VERSION "volvo_v40_2017_ptradar"

NS_ :

BS_:

BU_: XXX BCM CEM CVM DIM ECM FSM PSCM SAS SRS TCM Gateway ESR

BO_ 8 SAS0: 8 SAS
 SG_ SteeringDirection : 42|1@0+ (1,0) [0|1] "" XXX
 SG_ RelativeTurnDirection : 43|1@0+ (1,0) [0|1] "" XXX
 SG_ SteeringAngle : 53|14@0+ (0.04395,0) [0|65535] "degrees" XXX
 SG_ NEW_SIGNAL_1 : 47|4@0+ (1,0) [0|15] "" XXX
 SG_ NEW_SIGNAL_2 : 39|4@0+ (1,0) [0|15] "" XXX
 SG_ AngleRate : 21|14@0+ (0.075,0) [0|1500] "deg/S" XXX

BO_ 16 CCButtons: 8 CEM
 SG_ byte0 : 7|8@0+ (1,0) [0|255] "" XXX
 SG_ byte1 : 15|8@0+ (1,0) [0|255] "" XXX
 SG_ byte2 : 23|8@0+ (1,0) [0|255] "" XXX
 SG_ byte3 : 31|8@0+ (1,0) [0|255] "" XXX
 SG_ byte4 : 39|8@0+ (1,0) [0|255] "" XXX
 SG_ byte6 : 55|5@0+ (1,0) [0|31] "" XXX
 SG_ B7b0 : 56|1@0+ (1,0) [0|1] "" XXX
 SG_ B7b1 : 57|1@0+ (1,0) [0|1] "" XXX
 SG_ B7b6 : 62|1@0+ (1,0) [0|1] "" XXX
 SG_ ACCOnOffBtn : 58|1@0+ (1,0) [0|1] "" XXX
 SG_ ACCSetBtn : 63|1@0+ (1,0) [0|1] "" XXX
 SG_ ACCStopBtn : 60|1@0+ (1,0) [0|1] "" XXX
 SG_ ACCResumeBtn : 61|1@0+ (1,0) [0|1] "" XXX
 SG_ ACCMinusBtn : 48|1@0+ (1,0) [0|1] "" XXX
 SG_ TimeGapIncreaseBtn : 49|1@0+ (1,0) [0|1] "" XXX
 SG_ TimeGapDecreaseBtn : 50|1@0+ (1,0) [0|1] "" XXX
 SG_ byte5 : 47|8@0+ (1,0) [0|255] "" XXX
 SG_ B7b3 : 59|1@0+ (1,0) [0|1] "" XXX

BO_ 48 FSM0: 8 FSM
 SG_ ACCStatusTracking : 56|1@0+ (1,0) [0|1] "" XXX
 SG_ ACCStatusOnOff : 57|1@0+ (1,0) [0|1] "" XXX
 SG_ ACCStatusActive : 58|1@0+ (1,0) [0|1] "" XXX
 SG_ FCWSomething : 25|3@0+ (1,0) [0|3] "" XXX
 SG_ StatusSomething : 55|8@0+ (1,0) [0|255] "" XXX

BO_ 64 TCM0: 8 TCM
 SG_ RPMSomething : 42|11@0+ (1,0) [0|2047] "" XXX
 SG_ GearShifter : 46|2@0+ (1,0) [0|3] "" XXX

BO_ 85 PedalandBrake: 8 ECM
 SG_ AccPedal : 9|10@0+ (0.1,0) [0|1023] "%" XXX
 SG_ BrakePedalActive2 : 24|1@0+ (1,0) [0|1] "" XXX
 SG_ NEW_SIGNAL_1 : 35|12@0+ (1,0) [0|4095] "" XXX
 SG_ BrakePedalActive : 38|1@0+ (1,0) [0|1] "" XXX
 SG_ NEW_SIGNAL_3 : 55|8@0+ (1,0) [0|255] "" XXX
 SG_ NEW_SIGNAL_2 : 63|8@0+ (1,0) [0|255] "" XXX

BO_ 101 EngineInfo: 8 XXX
 SG_ NEW_SIGNAL_1 : 17|10@0+ (1,-512) [0|1023] "" XXX
 SG_ EngineSpeed : 52|13@0+ (1,0) [0|1023] "" XXX

BO_ 112 NEW_MSG_4: 8 XXX
 SG_ NEW_SIGNAL_1 : 39|8@0+ (1,0) [0|255] "" XXX

BO_ 114 ECM1: 8 ECM
 SG_ NEW_SIGNAL_1 : 23|8@0+ (1,0) [0|255] "" XXX
 SG_ ECM_ACC_ONOFF_INV : 43|1@0+ (1,0) [0|1] "" XXX
 SG_ ECM_ACC_RESUME_INV : 45|1@0+ (1,0) [0|1] "" XXX
 SG_ ECM_ACC_SET_INV : 47|1@0+ (1,0) [0|1] "" XXX
 SG_ ECM_ACC_TIMEGAP_INC_INV : 33|1@0+ (1,0) [0|1] "" XXX
 SG_ ECM_ACC_DEC_INV : 32|1@0+ (1,0) [0|1] "" XXX
 SG_ ECM_ACC_TIMEGAP_DEC_INV : 34|1@0+ (1,0) [0|1] "" XXX

BO_ 117 ECM1_2: 8 ECM

BO_ 128 NEW_MSG_5: 8 XXX
 SG_ NEW_SIGNAL_2 : 26|11@0+ (1,0) [0|2047] "" XXX
 SG_ NEW_SIGNAL_1 : 52|13@0+ (1,0) [0|8191] "" XXX

BO_ 176 ECM2: 8 ECM
 SG_ NEW_SIGNAL_1 : 50|11@0+ (1,0) [0|2047] "" XXX
 SG_ NEW_SIGNAL_2 : 47|8@0+ (1,0) [0|63] "" XXX

BO_ 192 Gear: 8 XXX
 SG_ TransmissionGear : 36|3@0+ (1,1) [0|7] "" XXX

BO_ 208 FSM1: 8 FSM
 SG_ SET_X_E3 : 7|8@0+ (1,0) [0|255] "" XXX
 SG_ SET_X_B4 : 15|8@0+ (1,0) [0|255] "" XXX
 SG_ SET_X_08 : 23|8@0+ (1,0) [0|255] "" XXX
 SG_ TrqLim : 31|8@0+ (1,-128) [0|255] "" XXX
 SG_ Checksum : 55|8@0+ (1,0) [0|255] "" XXX
 SG_ LKASteerDirection : 57|2@0+ (1,0) [0|2] "" XXX
 SG_ SET_X_25 : 63|6@0+ (1,0) [0|63] "" XXX
 SG_ LKAAngleReq : 37|14@0+ (0.04395,-360.0384) [-360.0384|359.99445] "degrees" XXX
 SG_ SET_X_02 : 39|2@0+ (1,0) [0|3] "" XXX

BO_ 224 PSCM0: 8 PSCM
 SG_ NEW_SIGNAL_2 : 12|5@0+ (1,0) [0|31] "" XXX
 SG_ counter_07 : 15|3@0+ (1,0) [0|7] "" XXX
 SG_ counter2_07 : 37|3@0+ (1,0) [0|16383] "" XXX
 SG_ rate_of_something : 46|7@0+ (1,0) [0|62] "" XXX
 SG_ OneDuringDriving : 49|1@0+ (1,0) [0|1] "" XXX
 SG_ NEW_SIGNAL_1 : 63|1@0+ (1,0) [0|1] "" XXX

BO_ 245 wheelspeed0: 8 BCM
 SG_ counter1 : 21|6@0+ (1,0) [0|65535] "" XXX
 SG_ counter0 : 7|16@0+ (1,0) [0|65535] "" XXX
 SG_ WhlSpdLF : 39|16@0+ (1,0) [0|65535] "" XXX
 SG_ WhlSpdRF : 55|16@0+ (1,0) [0|65535] "" XXX

BO_ 272 SpeedSignal0: 8 XXX
 SG_ VehicleSpeedSignal : 55|16@0+ (0.01,0) [0|65535] "" XXX

BO_ 288 wheel_speed1: 8 BCM
 SG_ WhlSpdLR : 39|16@0+ (1,0) [0|65535] "" XXX
 SG_ WhlSpdRR : 55|16@0+ (1,0) [0|65535] "" XXX

BO_ 293 PSCM1: 8 PSCM
 SG_ byte0 : 7|8@0+ (1,0) [0|255] "" XXX
 SG_ byte3 : 31|8@0+ (1,0) [0|255] "" XXX
 SG_ byte4 : 39|8@0+ (1,0) [0|255] "" XXX
 SG_ byte7 : 63|8@0+ (1,0) [0|255] "" XXX
 SG_ LKATorque : 11|12@0+ (1,-2000) [0|4095] "" XXX
 SG_ SteeringAngleServo : 47|16@0+ (0.04395,-1440.1536) [0|65535] "deg" XXX
 SG_ LKAActive : 15|4@0+ (1,0) [0|15] "" XXX

BO_ 304 VehicleSpeed0: 8 BCM
 SG_ NEW_SIGNAL_2 : 15|16@0+ (1,0) [0|65535] "" XXX
 SG_ VehicleSpeed : 31|16@0+ (0.01,0) [0|65535] "km/h" XXX
 SG_ NEW_SIGNAL_1 : 55|16@0+ (1,0) [0|65535] "" XXX

VAL_TABLE_ ForwardReverse 1 "Reverse" 0 "Forward" ;
VAL_TABLE_ LeftRight 1 "Right Clockwise" 0 "Left CounterClockwise" ;
VAL_TABLE_ ValidInvalid 1 "Valid" 0 "Invalid" ;
VAL_TABLE_ TrueFalse 1 "True" 0 "False" ;

BO_ 325 ECM3: 8 ECM

BO_ 336 VehicleSpeed1: 8 BCM
 SG_ NEW_SIGNAL_2 : 31|16@0+ (1,0) [0|65535] "" XXX
 SG_ NEW_SIGNAL_1 : 15|16@0+ (1,0) [0|65535] "" XXX
 SG_ VehicleSpeed : 55|16@0+ (0.01,0) [0|65535] "" XXX

BO_ 352 FSM2: 8 FSM
 SG_ LkaDimLine : 51|2@1+ (1,0) [0|127] "" XXX
 SG_ ACC_AccelRequest : 63|8@0+ (0.066,-12.672) [-12.672|4.158] "m/s^2" XXX
 SG_ NEW_SIGNAL_1 : 55|1@0+ (1,0) [0|1] "" XXX
 SG_ Byte_0 : 7|8@0+ (1,0) [0|255] "" XXX
 SG_ Byte_1 : 15|8@0+ (1,0) [0|255] "" XXX
 SG_ Byte_2_b7_6 : 23|2@0+ (1,0) [0|3] "" XXX
 SG_ ACC_BrakeRequest : 21|1@0+ (1,0) [0|1] "" XXX
 SG_ Byte_2_b4_0 : 20|5@0+ (1,0) [0|31] "" XXX
 SG_ Byte_3 : 31|8@0+ (1,0) [0|255] "" XXX
 SG_ Byte_4 : 39|8@0+ (1,0) [0|255] "" XXX
 SG_ Byte_5_b7_6 : 47|2@0+ (1,0) [0|3] "" XXX
 SG_ ACC_BrakeRequest_B : 45|1@0+ (1,0) [0|1] "" XXX
 SG_ Byte_5_b4_0 : 44|5@0+ (1,0) [0|31] "" XXX

BO_ 432 BrakeMessages: 8 BCM
 SG_ BrakePress0 : 1|10@0+ (1,0) [0|1023] "" XXX
 SG_ BrakePress1 : 33|10@0+ (1,0) [0|1023] "" XXX
 SG_ BrakeStatus : 18|3@0+ (1,0) [0|7] "" XXX
 SG_ BrakeHold : 22|1@0+ (1,0) [0|1] "" XXX

BO_ 437 BrakeInfo: 8 XXX
 SG_ Byte_0 : 7|8@0+ (1,0) [0|255] "" XXX
 SG_ Byte_1 : 15|8@0+ (1,0) [0|255] "" XXX
 SG_ Byte_2 : 23|8@0+ (1,0) [0|255] "" XXX
 SG_ Byte_3 : 31|8@0+ (1,0) [0|255] "" XXX
 SG_ Byte_4 : 39|8@0+ (1,0) [0|255] "" XXX
 SG_ Byte_5 : 47|8@0+ (1,0) [0|255] "" XXX
 SG_ Byte_6 : 55|8@0+ (1,0) [0|255] "" XXX
 SG_ Byte_7 : 63|8@0+ (1,0) [0|255] "" XXX

BO_ 464 DIM0: 8 DIM

BO_ 480 BCM0: 8 BCM

BO_ 528 CEM0: 8 CEM
 SG_ LKA_State : 2|1@0+ (1,0) [0|1] "" XXX

BO_ 608 CVM0: 8 CVM
 SG_ NEW_SIGNAL_1 : 7|8@0+ (1,0) [0|255] "" XXX
 SG_ NEW_SIGNAL_2 : 15|5@0+ (1,0) [0|32] "" XXX
 SG_ Distance : 10|11@0+ (1,0) [0|2048] "" XXX

BO_ 624 FSM3: 8 FSM
 SG_ Byte_0 : 7|8@0+ (1,0) [0|255] "" XXX
 SG_ Byte_1 : 15|8@0+ (1,0) [0|255] "" XXX
 SG_ ACC_LeadDecelRaw : 23|16@0- (1,0) [-32768|32767] "" XXX
 SG_ Byte_4 : 39|8@0+ (1,0) [0|255] "" XXX
 SG_ Byte_5 : 47|8@0+ (1,0) [0|255] "" XXX
 SG_ Byte_6 : 55|8@0+ (1,0) [0|255] "" XXX
 SG_ Byte_7 : 63|8@0+ (1,0) [0|255] "" XXX

BO_ 640 FSM4: 8 FSM
 SG_ Byte_0 : 7|8@0+ (1,0) [0|255] "" XXX
 SG_ Byte_1 : 15|8@0+ (1,0) [0|255] "" XXX
 SG_ Byte_2 : 23|8@0+ (1,0) [0|255] "" XXX
 SG_ Byte_3 : 31|8@0+ (1,0) [0|255] "" XXX
 SG_ Byte_4 : 39|8@0+ (1,0) [0|255] "" XXX
 SG_ SpeedTarget : 47|8@0+ (1,0) [0|255] "" XXX
 SG_ Byte_6_b7_6 : 55|2@0+ (1,0) [0|3] "" XXX
 SG_ Byte_6_b5_3 : 53|3@0+ (1,0) [0|7] "" XXX
 SG_ Byte_6_b2 : 50|1@0+ (1,0) [0|1] "" XXX
 SG_ ACC_TractionRequest : 49|10@0+ (1,0) [0|1023] "" XXX

BO_ 648 SRS0: 8 SRS

BO_ 652 ECM4: 8 ECM

BO_ 656 ECM5: 8 ECM

BO_ 657 ECM6: 8 ECM

BO_ 681 MiscCarInfo: 8 CEM
 SG_ TurnSignal : 1|2@0+ (1,0) [0|3] "" XXX
 SG_ HighBeamOn : 52|1@0+ (1,0) [0|1] "" XXX

BO_ 693 ECM7: 8 ECM

BO_ 709 ACC: 8 ECM
 SG_ SpeedTargetACC : 0|9@0+ (0.5,0) [0|511] "" XXX
 SG_ ACC_PropulsionFeedback : 63|8@0+ (1,0) [0|255] "" XXX

BO_ 853 FSM5: 8 FSM
 SG_ TargetSpeedOdo : 23|8@0+ (1,0) [0|63] "kph" XXX
 SG_ SpeedSign : 36|5@0+ (5,0) [0|32] "" XXX
 SG_ TextUnderSign : 37|1@0+ (1,0) [0|1] "" XXX
 SG_ NEW_SIGNAL_6 : 39|3@0+ (1,0) [0|3] "" XXX
 SG_ NEW_SIGNAL_5 : 47|8@0+ (1,0) [0|255] "" XXX
 SG_ NEW_SIGNAL_3 : 31|8@0+ (1,0) [0|255] "" XXX
 SG_ LaneMarkingsOdo : 15|4@0+ (1,0) [0|7] "" XXX
 SG_ NEW_SIGNAL_2 : 11|4@0+ (1,0) [0|15] "" XXX
 SG_ NEW_SIGNAL_1 : 7|8@0+ (1,0) [0|255] "" XXX
 SG_ NEW_SIGNAL_4 : 55|16@0+ (1,0) [0|65535] "" XXX

BO_ 864 CEM1: 8 CEM
 SG_ ACC_DemandChangeFlag : 39|8@0+ (1,0) [0|255] "" XXX

BO_ 912 DIM1: 8 DIM

BO_ 968 SRS1: 8 SRS
 SG_ PassengerSeatBelt : 22|1@0+ (1,0) [0|1] "" XXX
 SG_ DriverSeatBelt : 19|1@0+ (1,0) [0|1] "" XXX

BO_ 1029 CEMBCM0: 8 CEM

BO_ 1830 diagCEMReq: 8 XXX
 SG_ byte0 : 7|8@0+ (1,0) [0|255] "" XXX
 SG_ byte1 : 15|8@0+ (1,0) [0|255] "" XXX
 SG_ byte2 : 23|8@0+ (1,0) [0|255] "" XXX
 SG_ byte3 : 31|8@0+ (1,0) [0|255] "" XXX
 SG_ byte4 : 39|8@0+ (1,0) [0|255] "" XXX
 SG_ byte5 : 47|8@0+ (1,0) [0|255] "" XXX
 SG_ byte6 : 55|8@0+ (1,0) [0|255] "" XXX
 SG_ byte7 : 63|8@0+ (1,0) [0|255] "" XXX

BO_ 1838 diagCEMResp: 8 XXX
 SG_ byte03 : 7|32@0+ (1,0) [0|4294967295] "" XXX
 SG_ byte47 : 39|32@0+ (1,0) [0|4294967295] "" XXX

BO_ 1840 diagPSCMReq: 8 XXX
 SG_ byte0 : 7|8@0+ (1,0) [0|255] "" XXX
 SG_ byte1 : 15|8@0+ (1,0) [0|255] "" XXX
 SG_ byte2 : 23|8@0+ (1,0) [0|255] "" XXX
 SG_ byte3 : 31|8@0+ (1,0) [0|255] "" XXX
 SG_ byte4 : 39|8@0+ (1,0) [0|255] "" XXX
 SG_ byte5 : 47|8@0+ (1,0) [0|255] "" XXX
 SG_ byte6 : 55|8@0+ (1,0) [0|255] "" XXX
 SG_ byte7 : 63|8@0+ (1,0) [0|255] "" XXX

BO_ 1848 diagPSCMResp: 8 XXX
 SG_ byte03 : 7|32@0+ (1,0) [0|4294967295] "" XXX
 SG_ byte47 : 39|32@0+ (1,0) [0|4294967295] "" XXX

BO_ 1892 diagFSMReq: 8 XXX
 SG_ byte0 : 7|8@0+ (1,0) [0|255] "" XXX
 SG_ byte1 : 15|8@0+ (1,0) [0|255] "" XXX
 SG_ byte2 : 23|8@0+ (1,0) [0|255] "" XXX
 SG_ byte3 : 31|8@0+ (1,0) [0|255] "" XXX
 SG_ byte4 : 39|8@0+ (1,0) [0|255] "" XXX
 SG_ byte5 : 47|8@0+ (1,0) [0|255] "" XXX
 SG_ byte6 : 55|8@0+ (1,0) [0|255] "" XXX
 SG_ byte7 : 63|8@0+ (1,0) [0|255] "" XXX

BO_ 1900 diagFSMResp: 8 XXX
 SG_ byte03 : 7|32@0+ (1,0) [0|4294967295] "" XXX
 SG_ byte47 : 39|32@0+ (1,0) [0|4294967295] "" XXX

BO_ 1939 diagCVMReq: 8 XXX
 SG_ byte0 : 7|8@0+ (1,0) [0|255] "" XXX
 SG_ byte1 : 15|8@0+ (1,0) [0|255] "" XXX
 SG_ byte2 : 23|8@0+ (1,0) [0|255] "" XXX
 SG_ byte3 : 31|8@0+ (1,0) [0|255] "" XXX
 SG_ byte4 : 39|8@0+ (1,0) [0|255] "" XXX
 SG_ byte5 : 47|8@0+ (1,0) [0|255] "" XXX
 SG_ byte6 : 55|8@0+ (1,0) [0|255] "" XXX
 SG_ byte7 : 63|8@0+ (1,0) [0|255] "" XXX

BO_ 1947 diagCVMResp: 8 XXX
 SG_ byte03 : 7|32@0+ (1,0) [0|4294967295] "" XXX
 SG_ byte47 : 39|32@0+ (1,0) [0|4294967295] "" XXX

BO_ 2015 diagGlobalReq: 8 XXX
 SG_ byte0 : 7|8@0+ (1,0) [0|255] "" XXX
 SG_ byte1 : 15|8@0+ (1,0) [0|255] "" XXX
 SG_ byte2 : 23|8@0+ (1,0) [0|255] "" XXX
 SG_ byte3 : 31|8@0+ (1,0) [0|255] "" XXX
 SG_ byte4 : 39|8@0+ (1,0) [0|255] "" XXX
 SG_ byte5 : 47|8@0+ (1,0) [0|255] "" XXX
 SG_ byte6 : 55|8@0+ (1,0) [0|255] "" XXX
 SG_ byte7 : 63|8@0+ (1,0) [0|255] "" XXX

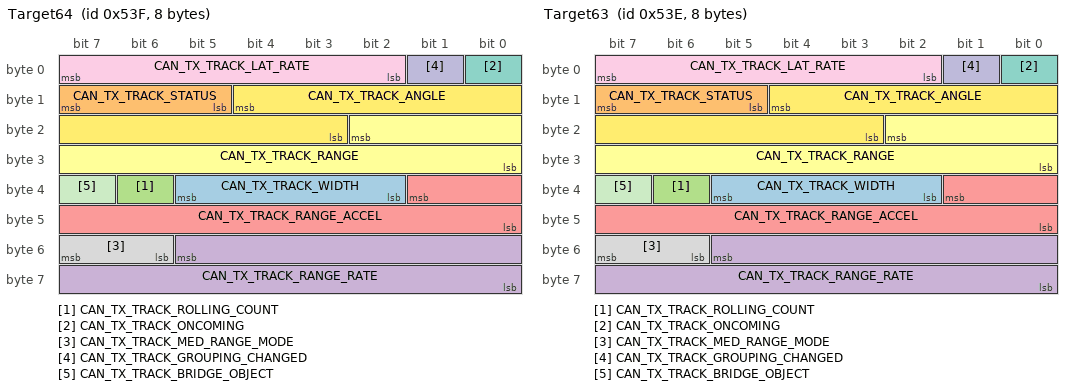
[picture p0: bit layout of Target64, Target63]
BO_ 1343 Target64: 8 Vector__XXX
 SG_ CAN_TX_TRACK_WIDTH : 37|4@0+ (0.5,0) [0|7.5] "" Vector__XXX
 SG_ CAN_TX_TRACK_STATUS : 15|3@0+ (1,0) [0|7] "" Vector__XXX
 SG_ CAN_TX_TRACK_ROLLING_COUNT : 38|1@0+ (1,0) [0|1] "" Vector__XXX
 SG_ CAN_TX_TRACK_RANGE_RATE : 53|14@0- (0.01,0) [-81.92|81.91] "m/s" Vector__XXX
 SG_ CAN_TX_TRACK_RANGE_ACCEL : 33|10@0- (0.05,0) [-25.6|25.55] "m/s^2" Vector__XXX
 SG_ CAN_TX_TRACK_RANGE : 18|11@0+ (0.1,0) [0|204.7] "m" Vector__XXX
 SG_ CAN_TX_TRACK_ONCOMING : 0|1@0+ (1,0) [0|1] "" Vector__XXX
 SG_ CAN_TX_TRACK_MED_RANGE_MODE : 55|2@0+ (1,0) [0|3] "" Vector__XXX
 SG_ CAN_TX_TRACK_LAT_RATE : 7|6@0- (0.25,0) [-8|7.75] "" Vector__XXX
 SG_ CAN_TX_TRACK_GROUPING_CHANGED : 1|1@0+ (1,0) [0|1] "" Vector__XXX
 SG_ CAN_TX_TRACK_BRIDGE_OBJECT : 39|1@0+ (1,0) [0|1] "" Vector__XXX
 SG_ CAN_TX_TRACK_ANGLE : 12|10@0- (0.1,0) [-51.2|51.1] "" Vector__XXX

BO_ 1342 Target63: 8 Vector__XXX
 SG_ CAN_TX_TRACK_WIDTH : 37|4@0+ (0.5,0) [0|7.5] "" Vector__XXX
 SG_ CAN_TX_TRACK_STATUS : 15|3@0+ (1,0) [0|7] "" Vector__XXX
 SG_ CAN_TX_TRACK_ROLLING_COUNT : 38|1@0+ (1,0) [0|1] "" Vector__XXX
 SG_ CAN_TX_TRACK_RANGE_RATE : 53|14@0- (0.01,0) [-81.92|81.91] "m/s" Vector__XXX
 SG_ CAN_TX_TRACK_RANGE_ACCEL : 33|10@0- (0.05,0) [-25.6|25.55] "m/s^2" Vector__XXX
 SG_ CAN_TX_TRACK_RANGE : 18|11@0+ (0.1,0) [0|204.7] "m" Vector__XXX
 SG_ CAN_TX_TRACK_ONCOMING : 0|1@0+ (1,0) [0|1] "" Vector__XXX
 SG_ CAN_TX_TRACK_MED_RANGE_MODE : 55|2@0+ (1,0) [0|3] "" Vector__XXX
 SG_ CAN_TX_TRACK_LAT_RATE : 7|6@0- (0.25,0) [-8|7.75] "" Vector__XXX
 SG_ CAN_TX_TRACK_GROUPING_CHANGED : 1|1@0+ (1,0) [0|1] "" Vector__XXX
 SG_ CAN_TX_TRACK_BRIDGE_OBJECT : 39|1@0+ (1,0) [0|1] "" Vector__XXX
 SG_ CAN_TX_TRACK_ANGLE : 12|10@0- (0.1,0) [-51.2|51.1] "" Vector__XXX

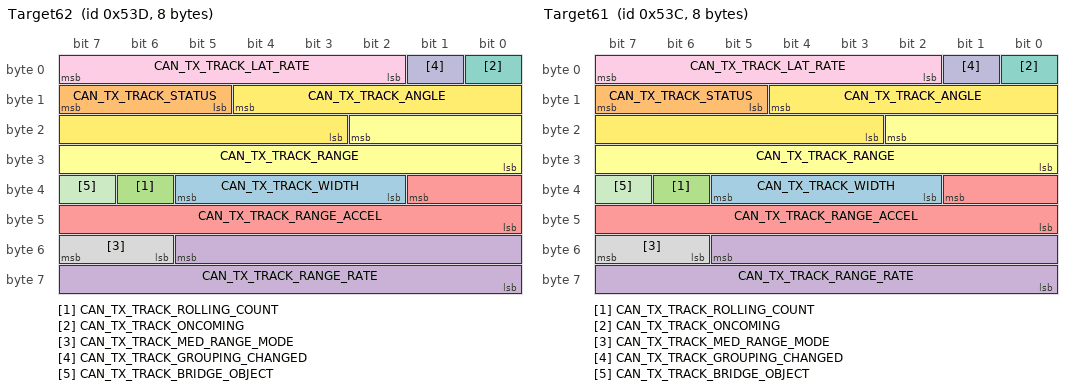
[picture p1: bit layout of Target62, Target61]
BO_ 1341 Target62: 8 Vector__XXX
 SG_ CAN_TX_TRACK_WIDTH : 37|4@0+ (0.5,0) [0|7.5] "" Vector__XXX
 SG_ CAN_TX_TRACK_STATUS : 15|3@0+ (1,0) [0|7] "" Vector__XXX
 SG_ CAN_TX_TRACK_ROLLING_COUNT : 38|1@0+ (1,0) [0|1] "" Vector__XXX
 SG_ CAN_TX_TRACK_RANGE_RATE : 53|14@0- (0.01,0) [-81.92|81.91] "m/s" Vector__XXX
 SG_ CAN_TX_TRACK_RANGE_ACCEL : 33|10@0- (0.05,0) [-25.6|25.55] "m/s^2" Vector__XXX
 SG_ CAN_TX_TRACK_RANGE : 18|11@0+ (0.1,0) [0|204.7] "m" Vector__XXX
 SG_ CAN_TX_TRACK_ONCOMING : 0|1@0+ (1,0) [0|1] "" Vector__XXX
 SG_ CAN_TX_TRACK_MED_RANGE_MODE : 55|2@0+ (1,0) [0|3] "" Vector__XXX
 SG_ CAN_TX_TRACK_LAT_RATE : 7|6@0- (0.25,0) [-8|7.75] "" Vector__XXX
 SG_ CAN_TX_TRACK_GROUPING_CHANGED : 1|1@0+ (1,0) [0|1] "" Vector__XXX
 SG_ CAN_TX_TRACK_BRIDGE_OBJECT : 39|1@0+ (1,0) [0|1] "" Vector__XXX
 SG_ CAN_TX_TRACK_ANGLE : 12|10@0- (0.1,0) [-51.2|51.1] "" Vector__XXX

BO_ 1340 Target61: 8 Vector__XXX
 SG_ CAN_TX_TRACK_WIDTH : 37|4@0+ (0.5,0) [0|7.5] "" Vector__XXX
 SG_ CAN_TX_TRACK_STATUS : 15|3@0+ (1,0) [0|7] "" Vector__XXX
 SG_ CAN_TX_TRACK_ROLLING_COUNT : 38|1@0+ (1,0) [0|1] "" Vector__XXX
 SG_ CAN_TX_TRACK_RANGE_RATE : 53|14@0- (0.01,0) [-81.92|81.91] "m/s" Vector__XXX
 SG_ CAN_TX_TRACK_RANGE_ACCEL : 33|10@0- (0.05,0) [-25.6|25.55] "m/s^2" Vector__XXX
 SG_ CAN_TX_TRACK_RANGE : 18|11@0+ (0.1,0) [0|204.7] "m" Vector__XXX
 SG_ CAN_TX_TRACK_ONCOMING : 0|1@0+ (1,0) [0|1] "" Vector__XXX
 SG_ CAN_TX_TRACK_MED_RANGE_MODE : 55|2@0+ (1,0) [0|3] "" Vector__XXX
 SG_ CAN_TX_TRACK_LAT_RATE : 7|6@0- (0.25,0) [-8|7.75] "" Vector__XXX
 SG_ CAN_TX_TRACK_GROUPING_CHANGED : 1|1@0+ (1,0) [0|1] "" Vector__XXX
 SG_ CAN_TX_TRACK_BRIDGE_OBJECT : 39|1@0+ (1,0) [0|1] "" Vector__XXX
 SG_ CAN_TX_TRACK_ANGLE : 12|10@0- (0.1,0) [-51.2|51.1] "" Vector__XXX

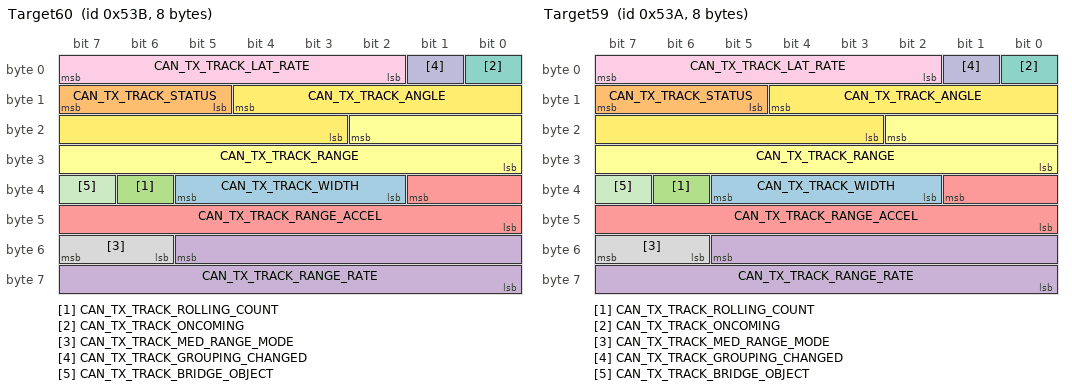
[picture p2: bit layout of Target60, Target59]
BO_ 1339 Target60: 8 Vector__XXX
 SG_ CAN_TX_TRACK_WIDTH : 37|4@0+ (0.5,0) [0|7.5] "" Vector__XXX
 SG_ CAN_TX_TRACK_STATUS : 15|3@0+ (1,0) [0|7] "" Vector__XXX
 SG_ CAN_TX_TRACK_ROLLING_COUNT : 38|1@0+ (1,0) [0|1] "" Vector__XXX
 SG_ CAN_TX_TRACK_RANGE_RATE : 53|14@0- (0.01,0) [-81.92|81.91] "m/s" Vector__XXX
 SG_ CAN_TX_TRACK_RANGE_ACCEL : 33|10@0- (0.05,0) [-25.6|25.55] "m/s^2" Vector__XXX
 SG_ CAN_TX_TRACK_RANGE : 18|11@0+ (0.1,0) [0|204.7] "m" Vector__XXX
 SG_ CAN_TX_TRACK_ONCOMING : 0|1@0+ (1,0) [0|1] "" Vector__XXX
 SG_ CAN_TX_TRACK_MED_RANGE_MODE : 55|2@0+ (1,0) [0|3] "" Vector__XXX
 SG_ CAN_TX_TRACK_LAT_RATE : 7|6@0- (0.25,0) [-8|7.75] "" Vector__XXX
 SG_ CAN_TX_TRACK_GROUPING_CHANGED : 1|1@0+ (1,0) [0|1] "" Vector__XXX
 SG_ CAN_TX_TRACK_BRIDGE_OBJECT : 39|1@0+ (1,0) [0|1] "" Vector__XXX
 SG_ CAN_TX_TRACK_ANGLE : 12|10@0- (0.1,0) [-51.2|51.1] "" Vector__XXX

BO_ 1338 Target59: 8 Vector__XXX
 SG_ CAN_TX_TRACK_WIDTH : 37|4@0+ (0.5,0) [0|7.5] "" Vector__XXX
 SG_ CAN_TX_TRACK_STATUS : 15|3@0+ (1,0) [0|7] "" Vector__XXX
 SG_ CAN_TX_TRACK_ROLLING_COUNT : 38|1@0+ (1,0) [0|1] "" Vector__XXX
 SG_ CAN_TX_TRACK_RANGE_RATE : 53|14@0- (0.01,0) [-81.92|81.91] "m/s" Vector__XXX
 SG_ CAN_TX_TRACK_RANGE_ACCEL : 33|10@0- (0.05,0) [-25.6|25.55] "m/s^2" Vector__XXX
 SG_ CAN_TX_TRACK_RANGE : 18|11@0+ (0.1,0) [0|204.7] "m" Vector__XXX
 SG_ CAN_TX_TRACK_ONCOMING : 0|1@0+ (1,0) [0|1] "" Vector__XXX
 SG_ CAN_TX_TRACK_MED_RANGE_MODE : 55|2@0+ (1,0) [0|3] "" Vector__XXX
 SG_ CAN_TX_TRACK_LAT_RATE : 7|6@0- (0.25,0) [-8|7.75] "" Vector__XXX
 SG_ CAN_TX_TRACK_GROUPING_CHANGED : 1|1@0+ (1,0) [0|1] "" Vector__XXX
 SG_ CAN_TX_TRACK_BRIDGE_OBJECT : 39|1@0+ (1,0) [0|1] "" Vector__XXX
 SG_ CAN_TX_TRACK_ANGLE : 12|10@0- (0.1,0) [-51.2|51.1] "" Vector__XXX

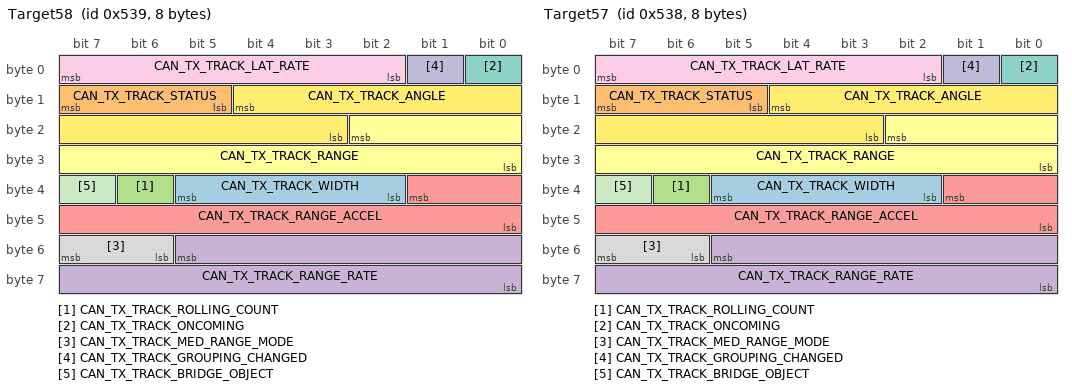
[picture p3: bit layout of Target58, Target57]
BO_ 1337 Target58: 8 Vector__XXX
 SG_ CAN_TX_TRACK_WIDTH : 37|4@0+ (0.5,0) [0|7.5] "" Vector__XXX
 SG_ CAN_TX_TRACK_STATUS : 15|3@0+ (1,0) [0|7] "" Vector__XXX
 SG_ CAN_TX_TRACK_ROLLING_COUNT : 38|1@0+ (1,0) [0|1] "" Vector__XXX
 SG_ CAN_TX_TRACK_RANGE_RATE : 53|14@0- (0.01,0) [-81.92|81.91] "m/s" Vector__XXX
 SG_ CAN_TX_TRACK_RANGE_ACCEL : 33|10@0- (0.05,0) [-25.6|25.55] "m/s^2" Vector__XXX
 SG_ CAN_TX_TRACK_RANGE : 18|11@0+ (0.1,0) [0|204.7] "m" Vector__XXX
 SG_ CAN_TX_TRACK_ONCOMING : 0|1@0+ (1,0) [0|1] "" Vector__XXX
 SG_ CAN_TX_TRACK_MED_RANGE_MODE : 55|2@0+ (1,0) [0|3] "" Vector__XXX
 SG_ CAN_TX_TRACK_LAT_RATE : 7|6@0- (0.25,0) [-8|7.75] "" Vector__XXX
 SG_ CAN_TX_TRACK_GROUPING_CHANGED : 1|1@0+ (1,0) [0|1] "" Vector__XXX
 SG_ CAN_TX_TRACK_BRIDGE_OBJECT : 39|1@0+ (1,0) [0|1] "" Vector__XXX
 SG_ CAN_TX_TRACK_ANGLE : 12|10@0- (0.1,0) [-51.2|51.1] "" Vector__XXX

BO_ 1336 Target57: 8 Vector__XXX
 SG_ CAN_TX_TRACK_WIDTH : 37|4@0+ (0.5,0) [0|7.5] "" Vector__XXX
 SG_ CAN_TX_TRACK_STATUS : 15|3@0+ (1,0) [0|7] "" Vector__XXX
 SG_ CAN_TX_TRACK_ROLLING_COUNT : 38|1@0+ (1,0) [0|1] "" Vector__XXX
 SG_ CAN_TX_TRACK_RANGE_RATE : 53|14@0- (0.01,0) [-81.92|81.91] "m/s" Vector__XXX
 SG_ CAN_TX_TRACK_RANGE_ACCEL : 33|10@0- (0.05,0) [-25.6|25.55] "m/s^2" Vector__XXX
 SG_ CAN_TX_TRACK_RANGE : 18|11@0+ (0.1,0) [0|204.7] "m" Vector__XXX
 SG_ CAN_TX_TRACK_ONCOMING : 0|1@0+ (1,0) [0|1] "" Vector__XXX
 SG_ CAN_TX_TRACK_MED_RANGE_MODE : 55|2@0+ (1,0) [0|3] "" Vector__XXX
 SG_ CAN_TX_TRACK_LAT_RATE : 7|6@0- (0.25,0) [-8|7.75] "" Vector__XXX
 SG_ CAN_TX_TRACK_GROUPING_CHANGED : 1|1@0+ (1,0) [0|1] "" Vector__XXX
 SG_ CAN_TX_TRACK_BRIDGE_OBJECT : 39|1@0+ (1,0) [0|1] "" Vector__XXX
 SG_ CAN_TX_TRACK_ANGLE : 12|10@0- (0.1,0) [-51.2|51.1] "" Vector__XXX

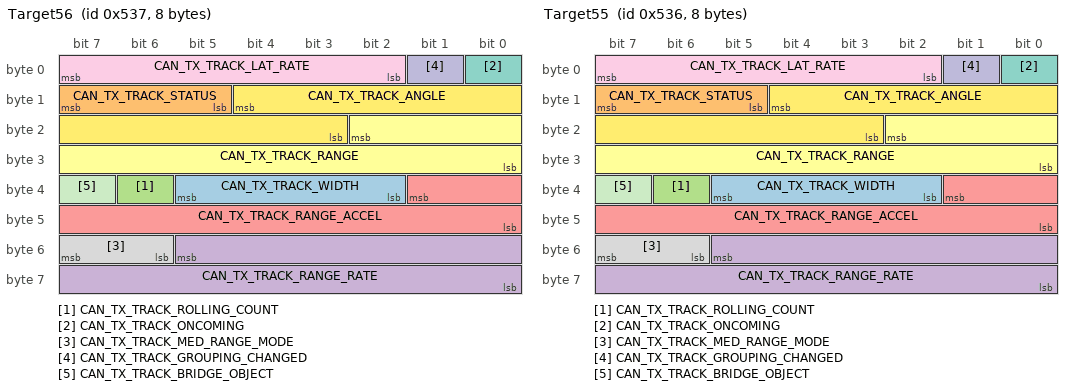
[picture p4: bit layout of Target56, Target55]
BO_ 1335 Target56: 8 Vector__XXX
 SG_ CAN_TX_TRACK_WIDTH : 37|4@0+ (0.5,0) [0|7.5] "" Vector__XXX
 SG_ CAN_TX_TRACK_STATUS : 15|3@0+ (1,0) [0|7] "" Vector__XXX
 SG_ CAN_TX_TRACK_ROLLING_COUNT : 38|1@0+ (1,0) [0|1] "" Vector__XXX
 SG_ CAN_TX_TRACK_RANGE_RATE : 53|14@0- (0.01,0) [-81.92|81.91] "m/s" Vector__XXX
 SG_ CAN_TX_TRACK_RANGE_ACCEL : 33|10@0- (0.05,0) [-25.6|25.55] "m/s^2" Vector__XXX
 SG_ CAN_TX_TRACK_RANGE : 18|11@0+ (0.1,0) [0|204.7] "m" Vector__XXX
 SG_ CAN_TX_TRACK_ONCOMING : 0|1@0+ (1,0) [0|1] "" Vector__XXX
 SG_ CAN_TX_TRACK_MED_RANGE_MODE : 55|2@0+ (1,0) [0|3] "" Vector__XXX
 SG_ CAN_TX_TRACK_LAT_RATE : 7|6@0- (0.25,0) [-8|7.75] "" Vector__XXX
 SG_ CAN_TX_TRACK_GROUPING_CHANGED : 1|1@0+ (1,0) [0|1] "" Vector__XXX
 SG_ CAN_TX_TRACK_BRIDGE_OBJECT : 39|1@0+ (1,0) [0|1] "" Vector__XXX
 SG_ CAN_TX_TRACK_ANGLE : 12|10@0- (0.1,0) [-51.2|51.1] "" Vector__XXX

BO_ 1334 Target55: 8 Vector__XXX
 SG_ CAN_TX_TRACK_WIDTH : 37|4@0+ (0.5,0) [0|7.5] "" Vector__XXX
 SG_ CAN_TX_TRACK_STATUS : 15|3@0+ (1,0) [0|7] "" Vector__XXX
 SG_ CAN_TX_TRACK_ROLLING_COUNT : 38|1@0+ (1,0) [0|1] "" Vector__XXX
 SG_ CAN_TX_TRACK_RANGE_RATE : 53|14@0- (0.01,0) [-81.92|81.91] "m/s" Vector__XXX
 SG_ CAN_TX_TRACK_RANGE_ACCEL : 33|10@0- (0.05,0) [-25.6|25.55] "m/s^2" Vector__XXX
 SG_ CAN_TX_TRACK_RANGE : 18|11@0+ (0.1,0) [0|204.7] "m" Vector__XXX
 SG_ CAN_TX_TRACK_ONCOMING : 0|1@0+ (1,0) [0|1] "" Vector__XXX
 SG_ CAN_TX_TRACK_MED_RANGE_MODE : 55|2@0+ (1,0) [0|3] "" Vector__XXX
 SG_ CAN_TX_TRACK_LAT_RATE : 7|6@0- (0.25,0) [-8|7.75] "" Vector__XXX
 SG_ CAN_TX_TRACK_GROUPING_CHANGED : 1|1@0+ (1,0) [0|1] "" Vector__XXX
 SG_ CAN_TX_TRACK_BRIDGE_OBJECT : 39|1@0+ (1,0) [0|1] "" Vector__XXX
 SG_ CAN_TX_TRACK_ANGLE : 12|10@0- (0.1,0) [-51.2|51.1] "" Vector__XXX

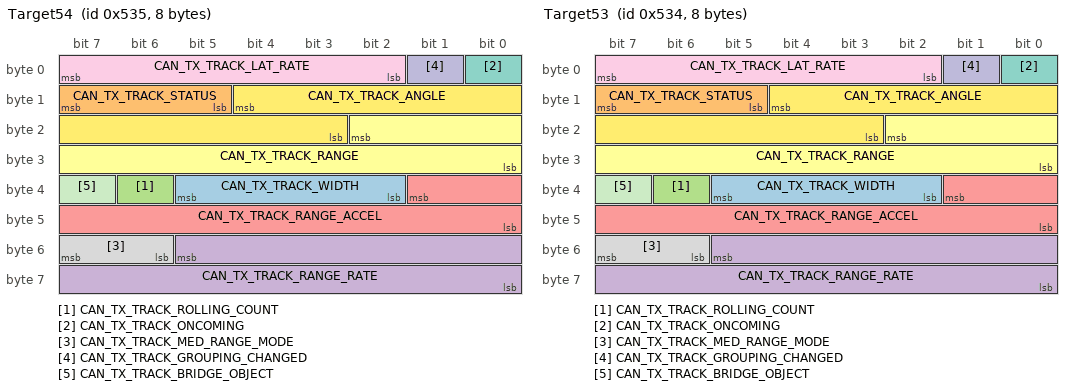
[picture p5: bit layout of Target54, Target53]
BO_ 1333 Target54: 8 Vector__XXX
 SG_ CAN_TX_TRACK_WIDTH : 37|4@0+ (0.5,0) [0|7.5] "" Vector__XXX
 SG_ CAN_TX_TRACK_STATUS : 15|3@0+ (1,0) [0|7] "" Vector__XXX
 SG_ CAN_TX_TRACK_ROLLING_COUNT : 38|1@0+ (1,0) [0|1] "" Vector__XXX
 SG_ CAN_TX_TRACK_RANGE_RATE : 53|14@0- (0.01,0) [-81.92|81.91] "m/s" Vector__XXX
 SG_ CAN_TX_TRACK_RANGE_ACCEL : 33|10@0- (0.05,0) [-25.6|25.55] "m/s^2" Vector__XXX
 SG_ CAN_TX_TRACK_RANGE : 18|11@0+ (0.1,0) [0|204.7] "m" Vector__XXX
 SG_ CAN_TX_TRACK_ONCOMING : 0|1@0+ (1,0) [0|1] "" Vector__XXX
 SG_ CAN_TX_TRACK_MED_RANGE_MODE : 55|2@0+ (1,0) [0|3] "" Vector__XXX
 SG_ CAN_TX_TRACK_LAT_RATE : 7|6@0- (0.25,0) [-8|7.75] "" Vector__XXX
 SG_ CAN_TX_TRACK_GROUPING_CHANGED : 1|1@0+ (1,0) [0|1] "" Vector__XXX
 SG_ CAN_TX_TRACK_BRIDGE_OBJECT : 39|1@0+ (1,0) [0|1] "" Vector__XXX
 SG_ CAN_TX_TRACK_ANGLE : 12|10@0- (0.1,0) [-51.2|51.1] "" Vector__XXX

BO_ 1332 Target53: 8 Vector__XXX
 SG_ CAN_TX_TRACK_WIDTH : 37|4@0+ (0.5,0) [0|7.5] "" Vector__XXX
 SG_ CAN_TX_TRACK_STATUS : 15|3@0+ (1,0) [0|7] "" Vector__XXX
 SG_ CAN_TX_TRACK_ROLLING_COUNT : 38|1@0+ (1,0) [0|1] "" Vector__XXX
 SG_ CAN_TX_TRACK_RANGE_RATE : 53|14@0- (0.01,0) [-81.92|81.91] "m/s" Vector__XXX
 SG_ CAN_TX_TRACK_RANGE_ACCEL : 33|10@0- (0.05,0) [-25.6|25.55] "m/s^2" Vector__XXX
 SG_ CAN_TX_TRACK_RANGE : 18|11@0+ (0.1,0) [0|204.7] "m" Vector__XXX
 SG_ CAN_TX_TRACK_ONCOMING : 0|1@0+ (1,0) [0|1] "" Vector__XXX
 SG_ CAN_TX_TRACK_MED_RANGE_MODE : 55|2@0+ (1,0) [0|3] "" Vector__XXX
 SG_ CAN_TX_TRACK_LAT_RATE : 7|6@0- (0.25,0) [-8|7.75] "" Vector__XXX
 SG_ CAN_TX_TRACK_GROUPING_CHANGED : 1|1@0+ (1,0) [0|1] "" Vector__XXX
 SG_ CAN_TX_TRACK_BRIDGE_OBJECT : 39|1@0+ (1,0) [0|1] "" Vector__XXX
 SG_ CAN_TX_TRACK_ANGLE : 12|10@0- (0.1,0) [-51.2|51.1] "" Vector__XXX

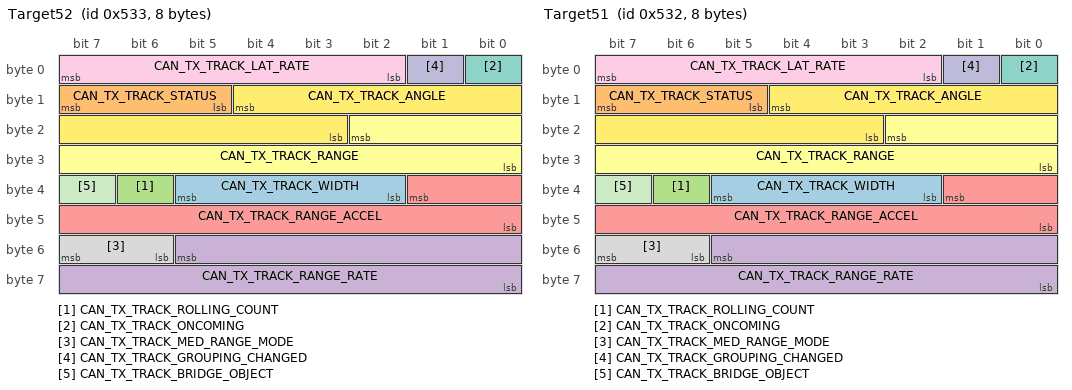
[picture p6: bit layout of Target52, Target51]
BO_ 1331 Target52: 8 Vector__XXX
 SG_ CAN_TX_TRACK_WIDTH : 37|4@0+ (0.5,0) [0|7.5] "" Vector__XXX
 SG_ CAN_TX_TRACK_STATUS : 15|3@0+ (1,0) [0|7] "" Vector__XXX
 SG_ CAN_TX_TRACK_ROLLING_COUNT : 38|1@0+ (1,0) [0|1] "" Vector__XXX
 SG_ CAN_TX_TRACK_RANGE_RATE : 53|14@0- (0.01,0) [-81.92|81.91] "m/s" Vector__XXX
 SG_ CAN_TX_TRACK_RANGE_ACCEL : 33|10@0- (0.05,0) [-25.6|25.55] "m/s^2" Vector__XXX
 SG_ CAN_TX_TRACK_RANGE : 18|11@0+ (0.1,0) [0|204.7] "m" Vector__XXX
 SG_ CAN_TX_TRACK_ONCOMING : 0|1@0+ (1,0) [0|1] "" Vector__XXX
 SG_ CAN_TX_TRACK_MED_RANGE_MODE : 55|2@0+ (1,0) [0|3] "" Vector__XXX
 SG_ CAN_TX_TRACK_LAT_RATE : 7|6@0- (0.25,0) [-8|7.75] "" Vector__XXX
 SG_ CAN_TX_TRACK_GROUPING_CHANGED : 1|1@0+ (1,0) [0|1] "" Vector__XXX
 SG_ CAN_TX_TRACK_BRIDGE_OBJECT : 39|1@0+ (1,0) [0|1] "" Vector__XXX
 SG_ CAN_TX_TRACK_ANGLE : 12|10@0- (0.1,0) [-51.2|51.1] "" Vector__XXX

BO_ 1330 Target51: 8 Vector__XXX
 SG_ CAN_TX_TRACK_WIDTH : 37|4@0+ (0.5,0) [0|7.5] "" Vector__XXX
 SG_ CAN_TX_TRACK_STATUS : 15|3@0+ (1,0) [0|7] "" Vector__XXX
 SG_ CAN_TX_TRACK_ROLLING_COUNT : 38|1@0+ (1,0) [0|1] "" Vector__XXX
 SG_ CAN_TX_TRACK_RANGE_RATE : 53|14@0- (0.01,0) [-81.92|81.91] "m/s" Vector__XXX
 SG_ CAN_TX_TRACK_RANGE_ACCEL : 33|10@0- (0.05,0) [-25.6|25.55] "m/s^2" Vector__XXX
 SG_ CAN_TX_TRACK_RANGE : 18|11@0+ (0.1,0) [0|204.7] "m" Vector__XXX
 SG_ CAN_TX_TRACK_ONCOMING : 0|1@0+ (1,0) [0|1] "" Vector__XXX
 SG_ CAN_TX_TRACK_MED_RANGE_MODE : 55|2@0+ (1,0) [0|3] "" Vector__XXX
 SG_ CAN_TX_TRACK_LAT_RATE : 7|6@0- (0.25,0) [-8|7.75] "" Vector__XXX
 SG_ CAN_TX_TRACK_GROUPING_CHANGED : 1|1@0+ (1,0) [0|1] "" Vector__XXX
 SG_ CAN_TX_TRACK_BRIDGE_OBJECT : 39|1@0+ (1,0) [0|1] "" Vector__XXX
 SG_ CAN_TX_TRACK_ANGLE : 12|10@0- (0.1,0) [-51.2|51.1] "" Vector__XXX

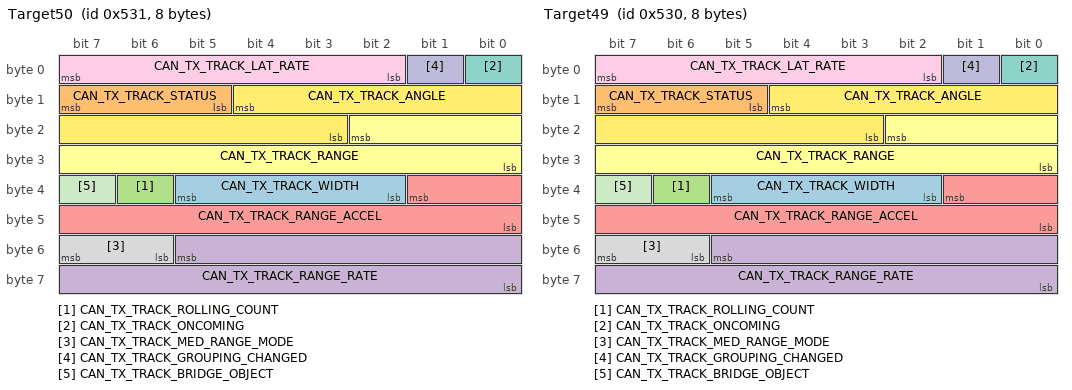
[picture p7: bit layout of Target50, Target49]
BO_ 1329 Target50: 8 Vector__XXX
 SG_ CAN_TX_TRACK_WIDTH : 37|4@0+ (0.5,0) [0|7.5] "" Vector__XXX
 SG_ CAN_TX_TRACK_STATUS : 15|3@0+ (1,0) [0|7] "" Vector__XXX
 SG_ CAN_TX_TRACK_ROLLING_COUNT : 38|1@0+ (1,0) [0|1] "" Vector__XXX
 SG_ CAN_TX_TRACK_RANGE_RATE : 53|14@0- (0.01,0) [-81.92|81.91] "m/s" Vector__XXX
 SG_ CAN_TX_TRACK_RANGE_ACCEL : 33|10@0- (0.05,0) [-25.6|25.55] "m/s^2" Vector__XXX
 SG_ CAN_TX_TRACK_RANGE : 18|11@0+ (0.1,0) [0|204.7] "m" Vector__XXX
 SG_ CAN_TX_TRACK_ONCOMING : 0|1@0+ (1,0) [0|1] "" Vector__XXX
 SG_ CAN_TX_TRACK_MED_RANGE_MODE : 55|2@0+ (1,0) [0|3] "" Vector__XXX
 SG_ CAN_TX_TRACK_LAT_RATE : 7|6@0- (0.25,0) [-8|7.75] "" Vector__XXX
 SG_ CAN_TX_TRACK_GROUPING_CHANGED : 1|1@0+ (1,0) [0|1] "" Vector__XXX
 SG_ CAN_TX_TRACK_BRIDGE_OBJECT : 39|1@0+ (1,0) [0|1] "" Vector__XXX
 SG_ CAN_TX_TRACK_ANGLE : 12|10@0- (0.1,0) [-51.2|51.1] "" Vector__XXX

BO_ 1328 Target49: 8 Vector__XXX
 SG_ CAN_TX_TRACK_WIDTH : 37|4@0+ (0.5,0) [0|7.5] "" Vector__XXX
 SG_ CAN_TX_TRACK_STATUS : 15|3@0+ (1,0) [0|7] "" Vector__XXX
 SG_ CAN_TX_TRACK_ROLLING_COUNT : 38|1@0+ (1,0) [0|1] "" Vector__XXX
 SG_ CAN_TX_TRACK_RANGE_RATE : 53|14@0- (0.01,0) [-81.92|81.91] "m/s" Vector__XXX
 SG_ CAN_TX_TRACK_RANGE_ACCEL : 33|10@0- (0.05,0) [-25.6|25.55] "m/s^2" Vector__XXX
 SG_ CAN_TX_TRACK_RANGE : 18|11@0+ (0.1,0) [0|204.7] "m" Vector__XXX
 SG_ CAN_TX_TRACK_ONCOMING : 0|1@0+ (1,0) [0|1] "" Vector__XXX
 SG_ CAN_TX_TRACK_MED_RANGE_MODE : 55|2@0+ (1,0) [0|3] "" Vector__XXX
 SG_ CAN_TX_TRACK_LAT_RATE : 7|6@0- (0.25,0) [-8|7.75] "" Vector__XXX
 SG_ CAN_TX_TRACK_GROUPING_CHANGED : 1|1@0+ (1,0) [0|1] "" Vector__XXX
 SG_ CAN_TX_TRACK_BRIDGE_OBJECT : 39|1@0+ (1,0) [0|1] "" Vector__XXX
 SG_ CAN_TX_TRACK_ANGLE : 12|10@0- (0.1,0) [-51.2|51.1] "" Vector__XXX

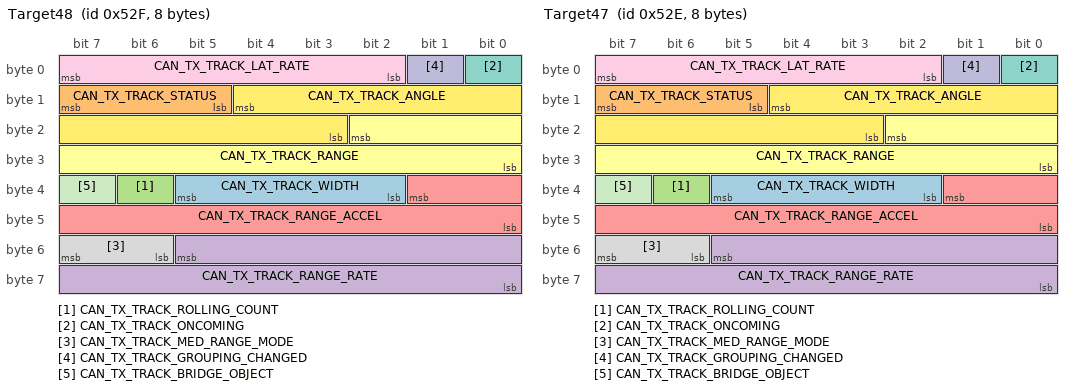
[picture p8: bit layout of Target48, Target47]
BO_ 1327 Target48: 8 Vector__XXX
 SG_ CAN_TX_TRACK_WIDTH : 37|4@0+ (0.5,0) [0|7.5] "" Vector__XXX
 SG_ CAN_TX_TRACK_STATUS : 15|3@0+ (1,0) [0|7] "" Vector__XXX
 SG_ CAN_TX_TRACK_ROLLING_COUNT : 38|1@0+ (1,0) [0|1] "" Vector__XXX
 SG_ CAN_TX_TRACK_RANGE_RATE : 53|14@0- (0.01,0) [-81.92|81.91] "m/s" Vector__XXX
 SG_ CAN_TX_TRACK_RANGE_ACCEL : 33|10@0- (0.05,0) [-25.6|25.55] "m/s^2" Vector__XXX
 SG_ CAN_TX_TRACK_RANGE : 18|11@0+ (0.1,0) [0|204.7] "m" Vector__XXX
 SG_ CAN_TX_TRACK_ONCOMING : 0|1@0+ (1,0) [0|1] "" Vector__XXX
 SG_ CAN_TX_TRACK_MED_RANGE_MODE : 55|2@0+ (1,0) [0|3] "" Vector__XXX
 SG_ CAN_TX_TRACK_LAT_RATE : 7|6@0- (0.25,0) [-8|7.75] "" Vector__XXX
 SG_ CAN_TX_TRACK_GROUPING_CHANGED : 1|1@0+ (1,0) [0|1] "" Vector__XXX
 SG_ CAN_TX_TRACK_BRIDGE_OBJECT : 39|1@0+ (1,0) [0|1] "" Vector__XXX
 SG_ CAN_TX_TRACK_ANGLE : 12|10@0- (0.1,0) [-51.2|51.1] "" Vector__XXX

BO_ 1326 Target47: 8 Vector__XXX
 SG_ CAN_TX_TRACK_WIDTH : 37|4@0+ (0.5,0) [0|7.5] "" Vector__XXX
 SG_ CAN_TX_TRACK_STATUS : 15|3@0+ (1,0) [0|7] "" Vector__XXX
 SG_ CAN_TX_TRACK_ROLLING_COUNT : 38|1@0+ (1,0) [0|1] "" Vector__XXX
 SG_ CAN_TX_TRACK_RANGE_RATE : 53|14@0- (0.01,0) [-81.92|81.91] "m/s" Vector__XXX
 SG_ CAN_TX_TRACK_RANGE_ACCEL : 33|10@0- (0.05,0) [-25.6|25.55] "m/s^2" Vector__XXX
 SG_ CAN_TX_TRACK_RANGE : 18|11@0+ (0.1,0) [0|204.7] "m" Vector__XXX
 SG_ CAN_TX_TRACK_ONCOMING : 0|1@0+ (1,0) [0|1] "" Vector__XXX
 SG_ CAN_TX_TRACK_MED_RANGE_MODE : 55|2@0+ (1,0) [0|3] "" Vector__XXX
 SG_ CAN_TX_TRACK_LAT_RATE : 7|6@0- (0.25,0) [-8|7.75] "" Vector__XXX
 SG_ CAN_TX_TRACK_GROUPING_CHANGED : 1|1@0+ (1,0) [0|1] "" Vector__XXX
 SG_ CAN_TX_TRACK_BRIDGE_OBJECT : 39|1@0+ (1,0) [0|1] "" Vector__XXX
 SG_ CAN_TX_TRACK_ANGLE : 12|10@0- (0.1,0) [-51.2|51.1] "" Vector__XXX

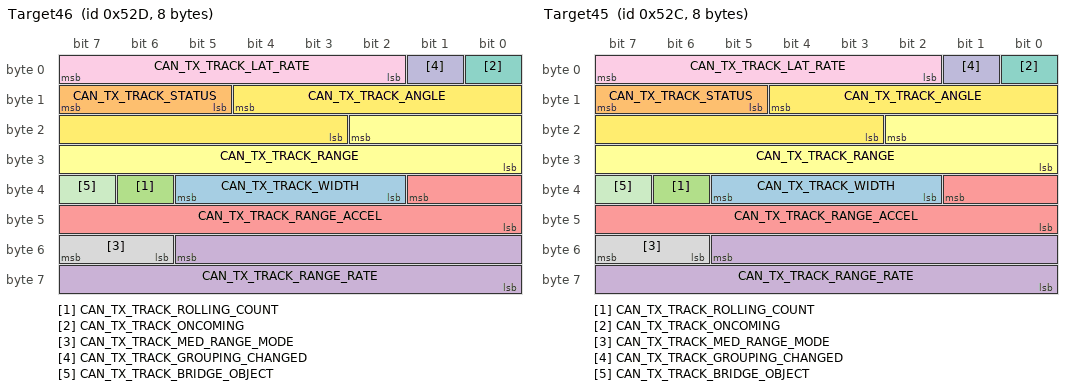
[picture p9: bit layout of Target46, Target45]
BO_ 1325 Target46: 8 Vector__XXX
 SG_ CAN_TX_TRACK_WIDTH : 37|4@0+ (0.5,0) [0|7.5] "" Vector__XXX
 SG_ CAN_TX_TRACK_STATUS : 15|3@0+ (1,0) [0|7] "" Vector__XXX
 SG_ CAN_TX_TRACK_ROLLING_COUNT : 38|1@0+ (1,0) [0|1] "" Vector__XXX
 SG_ CAN_TX_TRACK_RANGE_RATE : 53|14@0- (0.01,0) [-81.92|81.91] "m/s" Vector__XXX
 SG_ CAN_TX_TRACK_RANGE_ACCEL : 33|10@0- (0.05,0) [-25.6|25.55] "m/s^2" Vector__XXX
 SG_ CAN_TX_TRACK_RANGE : 18|11@0+ (0.1,0) [0|204.7] "m" Vector__XXX
 SG_ CAN_TX_TRACK_ONCOMING : 0|1@0+ (1,0) [0|1] "" Vector__XXX
 SG_ CAN_TX_TRACK_MED_RANGE_MODE : 55|2@0+ (1,0) [0|3] "" Vector__XXX
 SG_ CAN_TX_TRACK_LAT_RATE : 7|6@0- (0.25,0) [-8|7.75] "" Vector__XXX
 SG_ CAN_TX_TRACK_GROUPING_CHANGED : 1|1@0+ (1,0) [0|1] "" Vector__XXX
 SG_ CAN_TX_TRACK_BRIDGE_OBJECT : 39|1@0+ (1,0) [0|1] "" Vector__XXX
 SG_ CAN_TX_TRACK_ANGLE : 12|10@0- (0.1,0) [-51.2|51.1] "" Vector__XXX

BO_ 1324 Target45: 8 Vector__XXX
 SG_ CAN_TX_TRACK_WIDTH : 37|4@0+ (0.5,0) [0|7.5] "" Vector__XXX
 SG_ CAN_TX_TRACK_STATUS : 15|3@0+ (1,0) [0|7] "" Vector__XXX
 SG_ CAN_TX_TRACK_ROLLING_COUNT : 38|1@0+ (1,0) [0|1] "" Vector__XXX
 SG_ CAN_TX_TRACK_RANGE_RATE : 53|14@0- (0.01,0) [-81.92|81.91] "m/s" Vector__XXX
 SG_ CAN_TX_TRACK_RANGE_ACCEL : 33|10@0- (0.05,0) [-25.6|25.55] "m/s^2" Vector__XXX
 SG_ CAN_TX_TRACK_RANGE : 18|11@0+ (0.1,0) [0|204.7] "m" Vector__XXX
 SG_ CAN_TX_TRACK_ONCOMING : 0|1@0+ (1,0) [0|1] "" Vector__XXX
 SG_ CAN_TX_TRACK_MED_RANGE_MODE : 55|2@0+ (1,0) [0|3] "" Vector__XXX
 SG_ CAN_TX_TRACK_LAT_RATE : 7|6@0- (0.25,0) [-8|7.75] "" Vector__XXX
 SG_ CAN_TX_TRACK_GROUPING_CHANGED : 1|1@0+ (1,0) [0|1] "" Vector__XXX
 SG_ CAN_TX_TRACK_BRIDGE_OBJECT : 39|1@0+ (1,0) [0|1] "" Vector__XXX
 SG_ CAN_TX_TRACK_ANGLE : 12|10@0- (0.1,0) [-51.2|51.1] "" Vector__XXX

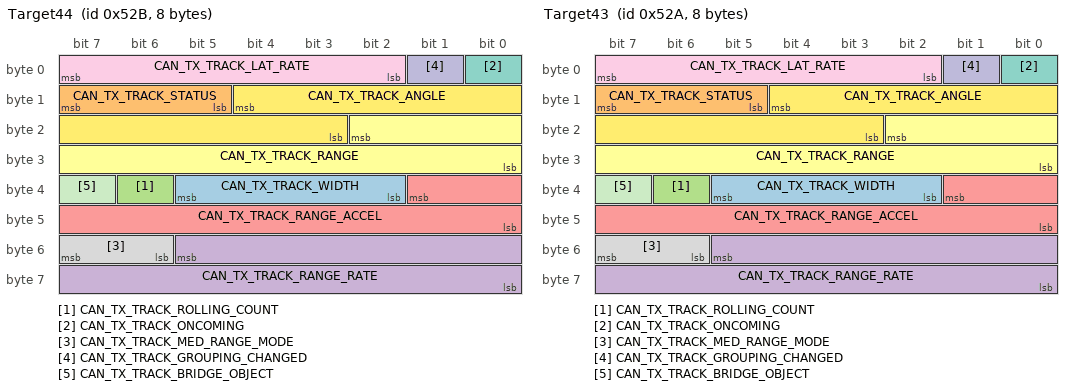
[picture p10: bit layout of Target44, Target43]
BO_ 1323 Target44: 8 Vector__XXX
 SG_ CAN_TX_TRACK_WIDTH : 37|4@0+ (0.5,0) [0|7.5] "" Vector__XXX
 SG_ CAN_TX_TRACK_STATUS : 15|3@0+ (1,0) [0|7] "" Vector__XXX
 SG_ CAN_TX_TRACK_ROLLING_COUNT : 38|1@0+ (1,0) [0|1] "" Vector__XXX
 SG_ CAN_TX_TRACK_RANGE_RATE : 53|14@0- (0.01,0) [-81.92|81.91] "m/s" Vector__XXX
 SG_ CAN_TX_TRACK_RANGE_ACCEL : 33|10@0- (0.05,0) [-25.6|25.55] "m/s^2" Vector__XXX
 SG_ CAN_TX_TRACK_RANGE : 18|11@0+ (0.1,0) [0|204.7] "m" Vector__XXX
 SG_ CAN_TX_TRACK_ONCOMING : 0|1@0+ (1,0) [0|1] "" Vector__XXX
 SG_ CAN_TX_TRACK_MED_RANGE_MODE : 55|2@0+ (1,0) [0|3] "" Vector__XXX
 SG_ CAN_TX_TRACK_LAT_RATE : 7|6@0- (0.25,0) [-8|7.75] "" Vector__XXX
 SG_ CAN_TX_TRACK_GROUPING_CHANGED : 1|1@0+ (1,0) [0|1] "" Vector__XXX
 SG_ CAN_TX_TRACK_BRIDGE_OBJECT : 39|1@0+ (1,0) [0|1] "" Vector__XXX
 SG_ CAN_TX_TRACK_ANGLE : 12|10@0- (0.1,0) [-51.2|51.1] "" Vector__XXX

BO_ 1322 Target43: 8 Vector__XXX
 SG_ CAN_TX_TRACK_WIDTH : 37|4@0+ (0.5,0) [0|7.5] "" Vector__XXX
 SG_ CAN_TX_TRACK_STATUS : 15|3@0+ (1,0) [0|7] "" Vector__XXX
 SG_ CAN_TX_TRACK_ROLLING_COUNT : 38|1@0+ (1,0) [0|1] "" Vector__XXX
 SG_ CAN_TX_TRACK_RANGE_RATE : 53|14@0- (0.01,0) [-81.92|81.91] "m/s" Vector__XXX
 SG_ CAN_TX_TRACK_RANGE_ACCEL : 33|10@0- (0.05,0) [-25.6|25.55] "m/s^2" Vector__XXX
 SG_ CAN_TX_TRACK_RANGE : 18|11@0+ (0.1,0) [0|204.7] "m" Vector__XXX
 SG_ CAN_TX_TRACK_ONCOMING : 0|1@0+ (1,0) [0|1] "" Vector__XXX
 SG_ CAN_TX_TRACK_MED_RANGE_MODE : 55|2@0+ (1,0) [0|3] "" Vector__XXX
 SG_ CAN_TX_TRACK_LAT_RATE : 7|6@0- (0.25,0) [-8|7.75] "" Vector__XXX
 SG_ CAN_TX_TRACK_GROUPING_CHANGED : 1|1@0+ (1,0) [0|1] "" Vector__XXX
 SG_ CAN_TX_TRACK_BRIDGE_OBJECT : 39|1@0+ (1,0) [0|1] "" Vector__XXX
 SG_ CAN_TX_TRACK_ANGLE : 12|10@0- (0.1,0) [-51.2|51.1] "" Vector__XXX

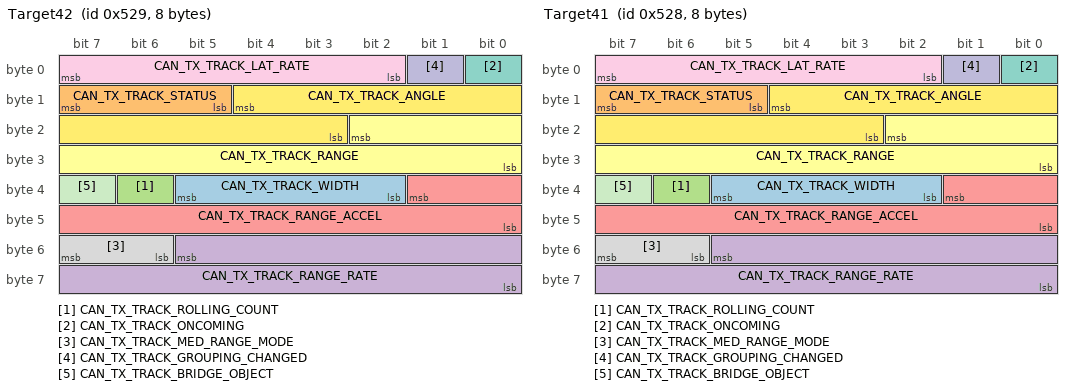
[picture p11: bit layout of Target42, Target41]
BO_ 1321 Target42: 8 Vector__XXX
 SG_ CAN_TX_TRACK_WIDTH : 37|4@0+ (0.5,0) [0|7.5] "" Vector__XXX
 SG_ CAN_TX_TRACK_STATUS : 15|3@0+ (1,0) [0|7] "" Vector__XXX
 SG_ CAN_TX_TRACK_ROLLING_COUNT : 38|1@0+ (1,0) [0|1] "" Vector__XXX
 SG_ CAN_TX_TRACK_RANGE_RATE : 53|14@0- (0.01,0) [-81.92|81.91] "m/s" Vector__XXX
 SG_ CAN_TX_TRACK_RANGE_ACCEL : 33|10@0- (0.05,0) [-25.6|25.55] "m/s^2" Vector__XXX
 SG_ CAN_TX_TRACK_RANGE : 18|11@0+ (0.1,0) [0|204.7] "m" Vector__XXX
 SG_ CAN_TX_TRACK_ONCOMING : 0|1@0+ (1,0) [0|1] "" Vector__XXX
 SG_ CAN_TX_TRACK_MED_RANGE_MODE : 55|2@0+ (1,0) [0|3] "" Vector__XXX
 SG_ CAN_TX_TRACK_LAT_RATE : 7|6@0- (0.25,0) [-8|7.75] "" Vector__XXX
 SG_ CAN_TX_TRACK_GROUPING_CHANGED : 1|1@0+ (1,0) [0|1] "" Vector__XXX
 SG_ CAN_TX_TRACK_BRIDGE_OBJECT : 39|1@0+ (1,0) [0|1] "" Vector__XXX
 SG_ CAN_TX_TRACK_ANGLE : 12|10@0- (0.1,0) [-51.2|51.1] "" Vector__XXX

BO_ 1320 Target41: 8 Vector__XXX
 SG_ CAN_TX_TRACK_WIDTH : 37|4@0+ (0.5,0) [0|7.5] "" Vector__XXX
 SG_ CAN_TX_TRACK_STATUS : 15|3@0+ (1,0) [0|7] "" Vector__XXX
 SG_ CAN_TX_TRACK_ROLLING_COUNT : 38|1@0+ (1,0) [0|1] "" Vector__XXX
 SG_ CAN_TX_TRACK_RANGE_RATE : 53|14@0- (0.01,0) [-81.92|81.91] "m/s" Vector__XXX
 SG_ CAN_TX_TRACK_RANGE_ACCEL : 33|10@0- (0.05,0) [-25.6|25.55] "m/s^2" Vector__XXX
 SG_ CAN_TX_TRACK_RANGE : 18|11@0+ (0.1,0) [0|204.7] "m" Vector__XXX
 SG_ CAN_TX_TRACK_ONCOMING : 0|1@0+ (1,0) [0|1] "" Vector__XXX
 SG_ CAN_TX_TRACK_MED_RANGE_MODE : 55|2@0+ (1,0) [0|3] "" Vector__XXX
 SG_ CAN_TX_TRACK_LAT_RATE : 7|6@0- (0.25,0) [-8|7.75] "" Vector__XXX
 SG_ CAN_TX_TRACK_GROUPING_CHANGED : 1|1@0+ (1,0) [0|1] "" Vector__XXX
 SG_ CAN_TX_TRACK_BRIDGE_OBJECT : 39|1@0+ (1,0) [0|1] "" Vector__XXX
 SG_ CAN_TX_TRACK_ANGLE : 12|10@0- (0.1,0) [-51.2|51.1] "" Vector__XXX

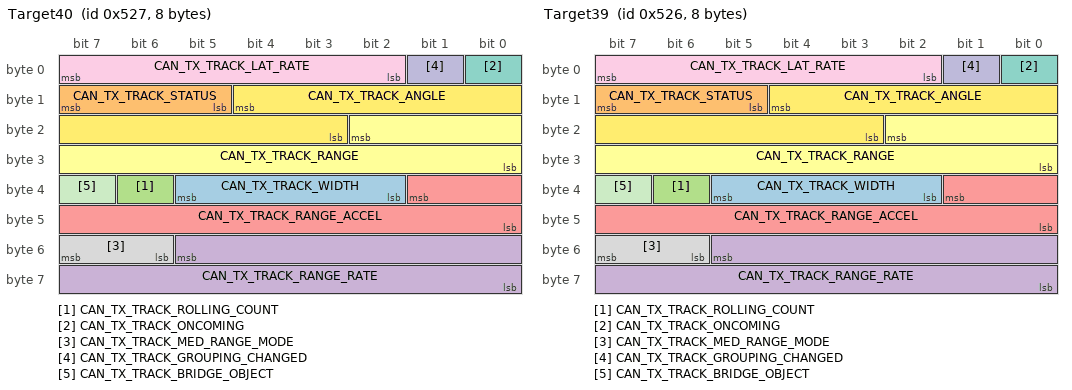
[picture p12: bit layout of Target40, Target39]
BO_ 1319 Target40: 8 Vector__XXX
 SG_ CAN_TX_TRACK_WIDTH : 37|4@0+ (0.5,0) [0|7.5] "" Vector__XXX
 SG_ CAN_TX_TRACK_STATUS : 15|3@0+ (1,0) [0|7] "" Vector__XXX
 SG_ CAN_TX_TRACK_ROLLING_COUNT : 38|1@0+ (1,0) [0|1] "" Vector__XXX
 SG_ CAN_TX_TRACK_RANGE_RATE : 53|14@0- (0.01,0) [-81.92|81.91] "m/s" Vector__XXX
 SG_ CAN_TX_TRACK_RANGE_ACCEL : 33|10@0- (0.05,0) [-25.6|25.55] "m/s^2" Vector__XXX
 SG_ CAN_TX_TRACK_RANGE : 18|11@0+ (0.1,0) [0|204.7] "m" Vector__XXX
 SG_ CAN_TX_TRACK_ONCOMING : 0|1@0+ (1,0) [0|1] "" Vector__XXX
 SG_ CAN_TX_TRACK_MED_RANGE_MODE : 55|2@0+ (1,0) [0|3] "" Vector__XXX
 SG_ CAN_TX_TRACK_LAT_RATE : 7|6@0- (0.25,0) [-8|7.75] "" Vector__XXX
 SG_ CAN_TX_TRACK_GROUPING_CHANGED : 1|1@0+ (1,0) [0|1] "" Vector__XXX
 SG_ CAN_TX_TRACK_BRIDGE_OBJECT : 39|1@0+ (1,0) [0|1] "" Vector__XXX
 SG_ CAN_TX_TRACK_ANGLE : 12|10@0- (0.1,0) [-51.2|51.1] "" Vector__XXX

BO_ 1318 Target39: 8 Vector__XXX
 SG_ CAN_TX_TRACK_WIDTH : 37|4@0+ (0.5,0) [0|7.5] "" Vector__XXX
 SG_ CAN_TX_TRACK_STATUS : 15|3@0+ (1,0) [0|7] "" Vector__XXX
 SG_ CAN_TX_TRACK_ROLLING_COUNT : 38|1@0+ (1,0) [0|1] "" Vector__XXX
 SG_ CAN_TX_TRACK_RANGE_RATE : 53|14@0- (0.01,0) [-81.92|81.91] "m/s" Vector__XXX
 SG_ CAN_TX_TRACK_RANGE_ACCEL : 33|10@0- (0.05,0) [-25.6|25.55] "m/s^2" Vector__XXX
 SG_ CAN_TX_TRACK_RANGE : 18|11@0+ (0.1,0) [0|204.7] "m" Vector__XXX
 SG_ CAN_TX_TRACK_ONCOMING : 0|1@0+ (1,0) [0|1] "" Vector__XXX
 SG_ CAN_TX_TRACK_MED_RANGE_MODE : 55|2@0+ (1,0) [0|3] "" Vector__XXX
 SG_ CAN_TX_TRACK_LAT_RATE : 7|6@0- (0.25,0) [-8|7.75] "" Vector__XXX
 SG_ CAN_TX_TRACK_GROUPING_CHANGED : 1|1@0+ (1,0) [0|1] "" Vector__XXX
 SG_ CAN_TX_TRACK_BRIDGE_OBJECT : 39|1@0+ (1,0) [0|1] "" Vector__XXX
 SG_ CAN_TX_TRACK_ANGLE : 12|10@0- (0.1,0) [-51.2|51.1] "" Vector__XXX

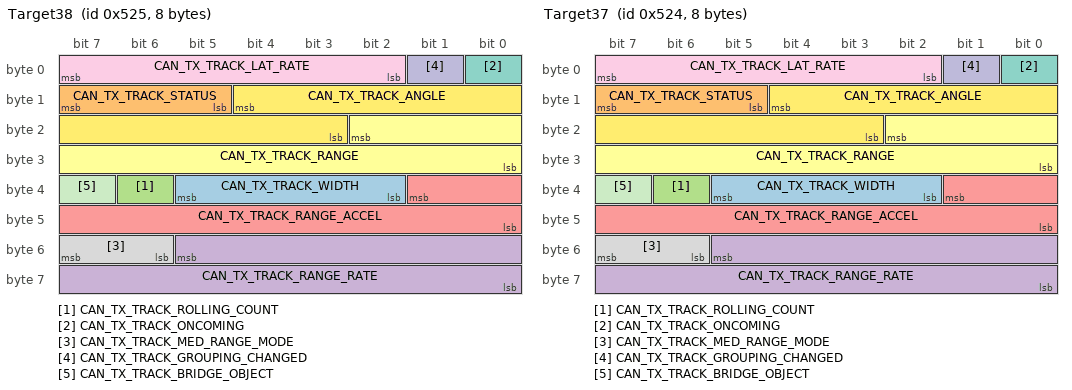
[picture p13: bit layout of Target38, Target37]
BO_ 1317 Target38: 8 Vector__XXX
 SG_ CAN_TX_TRACK_WIDTH : 37|4@0+ (0.5,0) [0|7.5] "" Vector__XXX
 SG_ CAN_TX_TRACK_STATUS : 15|3@0+ (1,0) [0|7] "" Vector__XXX
 SG_ CAN_TX_TRACK_ROLLING_COUNT : 38|1@0+ (1,0) [0|1] "" Vector__XXX
 SG_ CAN_TX_TRACK_RANGE_RATE : 53|14@0- (0.01,0) [-81.92|81.91] "m/s" Vector__XXX
 SG_ CAN_TX_TRACK_RANGE_ACCEL : 33|10@0- (0.05,0) [-25.6|25.55] "m/s^2" Vector__XXX
 SG_ CAN_TX_TRACK_RANGE : 18|11@0+ (0.1,0) [0|204.7] "m" Vector__XXX
 SG_ CAN_TX_TRACK_ONCOMING : 0|1@0+ (1,0) [0|1] "" Vector__XXX
 SG_ CAN_TX_TRACK_MED_RANGE_MODE : 55|2@0+ (1,0) [0|3] "" Vector__XXX
 SG_ CAN_TX_TRACK_LAT_RATE : 7|6@0- (0.25,0) [-8|7.75] "" Vector__XXX
 SG_ CAN_TX_TRACK_GROUPING_CHANGED : 1|1@0+ (1,0) [0|1] "" Vector__XXX
 SG_ CAN_TX_TRACK_BRIDGE_OBJECT : 39|1@0+ (1,0) [0|1] "" Vector__XXX
 SG_ CAN_TX_TRACK_ANGLE : 12|10@0- (0.1,0) [-51.2|51.1] "" Vector__XXX

BO_ 1316 Target37: 8 Vector__XXX
 SG_ CAN_TX_TRACK_WIDTH : 37|4@0+ (0.5,0) [0|7.5] "" Vector__XXX
 SG_ CAN_TX_TRACK_STATUS : 15|3@0+ (1,0) [0|7] "" Vector__XXX
 SG_ CAN_TX_TRACK_ROLLING_COUNT : 38|1@0+ (1,0) [0|1] "" Vector__XXX
 SG_ CAN_TX_TRACK_RANGE_RATE : 53|14@0- (0.01,0) [-81.92|81.91] "m/s" Vector__XXX
 SG_ CAN_TX_TRACK_RANGE_ACCEL : 33|10@0- (0.05,0) [-25.6|25.55] "m/s^2" Vector__XXX
 SG_ CAN_TX_TRACK_RANGE : 18|11@0+ (0.1,0) [0|204.7] "m" Vector__XXX
 SG_ CAN_TX_TRACK_ONCOMING : 0|1@0+ (1,0) [0|1] "" Vector__XXX
 SG_ CAN_TX_TRACK_MED_RANGE_MODE : 55|2@0+ (1,0) [0|3] "" Vector__XXX
 SG_ CAN_TX_TRACK_LAT_RATE : 7|6@0- (0.25,0) [-8|7.75] "" Vector__XXX
 SG_ CAN_TX_TRACK_GROUPING_CHANGED : 1|1@0+ (1,0) [0|1] "" Vector__XXX
 SG_ CAN_TX_TRACK_BRIDGE_OBJECT : 39|1@0+ (1,0) [0|1] "" Vector__XXX
 SG_ CAN_TX_TRACK_ANGLE : 12|10@0- (0.1,0) [-51.2|51.1] "" Vector__XXX

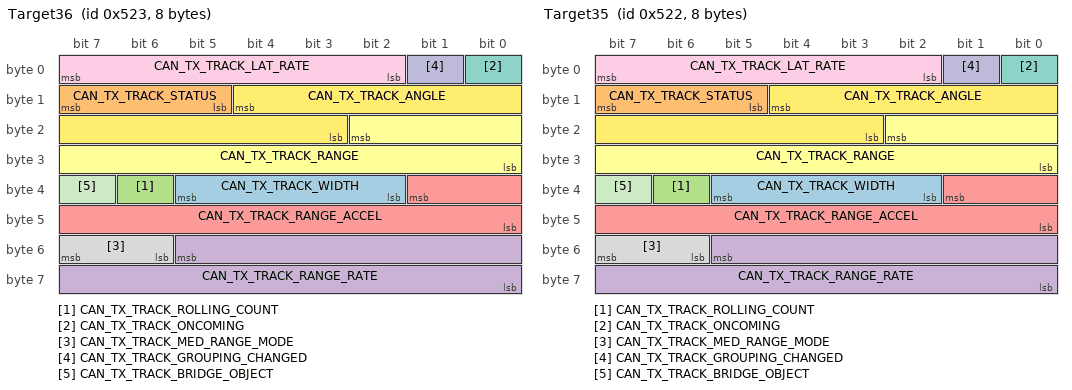
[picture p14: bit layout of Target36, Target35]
BO_ 1315 Target36: 8 Vector__XXX
 SG_ CAN_TX_TRACK_WIDTH : 37|4@0+ (0.5,0) [0|7.5] "" Vector__XXX
 SG_ CAN_TX_TRACK_STATUS : 15|3@0+ (1,0) [0|7] "" Vector__XXX
 SG_ CAN_TX_TRACK_ROLLING_COUNT : 38|1@0+ (1,0) [0|1] "" Vector__XXX
 SG_ CAN_TX_TRACK_RANGE_RATE : 53|14@0- (0.01,0) [-81.92|81.91] "m/s" Vector__XXX
 SG_ CAN_TX_TRACK_RANGE_ACCEL : 33|10@0- (0.05,0) [-25.6|25.55] "m/s^2" Vector__XXX
 SG_ CAN_TX_TRACK_RANGE : 18|11@0+ (0.1,0) [0|204.7] "m" Vector__XXX
 SG_ CAN_TX_TRACK_ONCOMING : 0|1@0+ (1,0) [0|1] "" Vector__XXX
 SG_ CAN_TX_TRACK_MED_RANGE_MODE : 55|2@0+ (1,0) [0|3] "" Vector__XXX
 SG_ CAN_TX_TRACK_LAT_RATE : 7|6@0- (0.25,0) [-8|7.75] "" Vector__XXX
 SG_ CAN_TX_TRACK_GROUPING_CHANGED : 1|1@0+ (1,0) [0|1] "" Vector__XXX
 SG_ CAN_TX_TRACK_BRIDGE_OBJECT : 39|1@0+ (1,0) [0|1] "" Vector__XXX
 SG_ CAN_TX_TRACK_ANGLE : 12|10@0- (0.1,0) [-51.2|51.1] "" Vector__XXX

BO_ 1314 Target35: 8 Vector__XXX
 SG_ CAN_TX_TRACK_WIDTH : 37|4@0+ (0.5,0) [0|7.5] "" Vector__XXX
 SG_ CAN_TX_TRACK_STATUS : 15|3@0+ (1,0) [0|7] "" Vector__XXX
 SG_ CAN_TX_TRACK_ROLLING_COUNT : 38|1@0+ (1,0) [0|1] "" Vector__XXX
 SG_ CAN_TX_TRACK_RANGE_RATE : 53|14@0- (0.01,0) [-81.92|81.91] "m/s" Vector__XXX
 SG_ CAN_TX_TRACK_RANGE_ACCEL : 33|10@0- (0.05,0) [-25.6|25.55] "m/s^2" Vector__XXX
 SG_ CAN_TX_TRACK_RANGE : 18|11@0+ (0.1,0) [0|204.7] "m" Vector__XXX
 SG_ CAN_TX_TRACK_ONCOMING : 0|1@0+ (1,0) [0|1] "" Vector__XXX
 SG_ CAN_TX_TRACK_MED_RANGE_MODE : 55|2@0+ (1,0) [0|3] "" Vector__XXX
 SG_ CAN_TX_TRACK_LAT_RATE : 7|6@0- (0.25,0) [-8|7.75] "" Vector__XXX
 SG_ CAN_TX_TRACK_GROUPING_CHANGED : 1|1@0+ (1,0) [0|1] "" Vector__XXX
 SG_ CAN_TX_TRACK_BRIDGE_OBJECT : 39|1@0+ (1,0) [0|1] "" Vector__XXX
 SG_ CAN_TX_TRACK_ANGLE : 12|10@0- (0.1,0) [-51.2|51.1] "" Vector__XXX

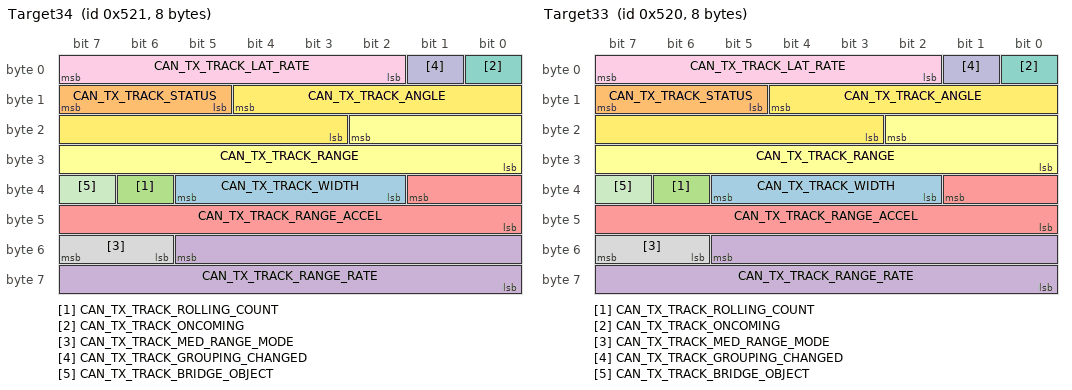
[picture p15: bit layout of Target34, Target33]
BO_ 1313 Target34: 8 Vector__XXX
 SG_ CAN_TX_TRACK_WIDTH : 37|4@0+ (0.5,0) [0|7.5] "" Vector__XXX
 SG_ CAN_TX_TRACK_STATUS : 15|3@0+ (1,0) [0|7] "" Vector__XXX
 SG_ CAN_TX_TRACK_ROLLING_COUNT : 38|1@0+ (1,0) [0|1] "" Vector__XXX
 SG_ CAN_TX_TRACK_RANGE_RATE : 53|14@0- (0.01,0) [-81.92|81.91] "m/s" Vector__XXX
 SG_ CAN_TX_TRACK_RANGE_ACCEL : 33|10@0- (0.05,0) [-25.6|25.55] "m/s^2" Vector__XXX
 SG_ CAN_TX_TRACK_RANGE : 18|11@0+ (0.1,0) [0|204.7] "m" Vector__XXX
 SG_ CAN_TX_TRACK_ONCOMING : 0|1@0+ (1,0) [0|1] "" Vector__XXX
 SG_ CAN_TX_TRACK_MED_RANGE_MODE : 55|2@0+ (1,0) [0|3] "" Vector__XXX
 SG_ CAN_TX_TRACK_LAT_RATE : 7|6@0- (0.25,0) [-8|7.75] "" Vector__XXX
 SG_ CAN_TX_TRACK_GROUPING_CHANGED : 1|1@0+ (1,0) [0|1] "" Vector__XXX
 SG_ CAN_TX_TRACK_BRIDGE_OBJECT : 39|1@0+ (1,0) [0|1] "" Vector__XXX
 SG_ CAN_TX_TRACK_ANGLE : 12|10@0- (0.1,0) [-51.2|51.1] "" Vector__XXX

BO_ 1312 Target33: 8 Vector__XXX
 SG_ CAN_TX_TRACK_WIDTH : 37|4@0+ (0.5,0) [0|7.5] "" Vector__XXX
 SG_ CAN_TX_TRACK_STATUS : 15|3@0+ (1,0) [0|7] "" Vector__XXX
 SG_ CAN_TX_TRACK_ROLLING_COUNT : 38|1@0+ (1,0) [0|1] "" Vector__XXX
 SG_ CAN_TX_TRACK_RANGE_RATE : 53|14@0- (0.01,0) [-81.92|81.91] "m/s" Vector__XXX
 SG_ CAN_TX_TRACK_RANGE_ACCEL : 33|10@0- (0.05,0) [-25.6|25.55] "m/s^2" Vector__XXX
 SG_ CAN_TX_TRACK_RANGE : 18|11@0+ (0.1,0) [0|204.7] "m" Vector__XXX
 SG_ CAN_TX_TRACK_ONCOMING : 0|1@0+ (1,0) [0|1] "" Vector__XXX
 SG_ CAN_TX_TRACK_MED_RANGE_MODE : 55|2@0+ (1,0) [0|3] "" Vector__XXX
 SG_ CAN_TX_TRACK_LAT_RATE : 7|6@0- (0.25,0) [-8|7.75] "" Vector__XXX
 SG_ CAN_TX_TRACK_GROUPING_CHANGED : 1|1@0+ (1,0) [0|1] "" Vector__XXX
 SG_ CAN_TX_TRACK_BRIDGE_OBJECT : 39|1@0+ (1,0) [0|1] "" Vector__XXX
 SG_ CAN_TX_TRACK_ANGLE : 12|10@0- (0.1,0) [-51.2|51.1] "" Vector__XXX

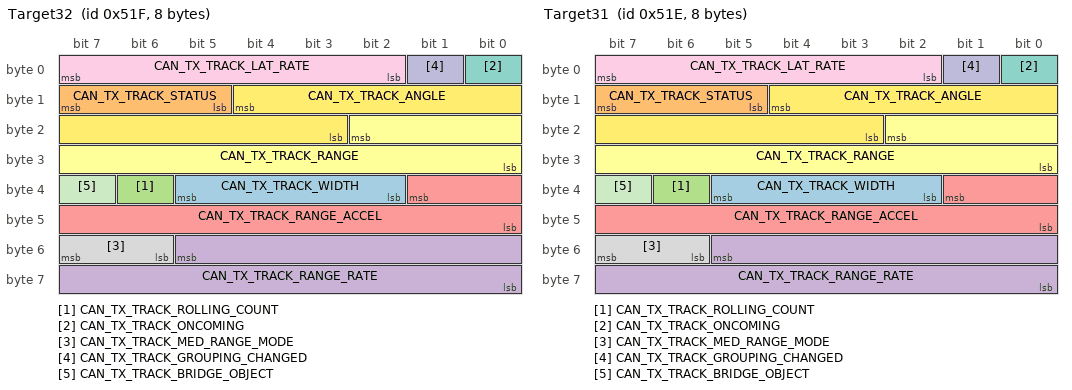
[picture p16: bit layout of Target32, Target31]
BO_ 1311 Target32: 8 Vector__XXX
 SG_ CAN_TX_TRACK_WIDTH : 37|4@0+ (0.5,0) [0|7.5] "" Vector__XXX
 SG_ CAN_TX_TRACK_STATUS : 15|3@0+ (1,0) [0|7] "" Vector__XXX
 SG_ CAN_TX_TRACK_ROLLING_COUNT : 38|1@0+ (1,0) [0|1] "" Vector__XXX
 SG_ CAN_TX_TRACK_RANGE_RATE : 53|14@0- (0.01,0) [-81.92|81.91] "m/s" Vector__XXX
 SG_ CAN_TX_TRACK_RANGE_ACCEL : 33|10@0- (0.05,0) [-25.6|25.55] "m/s^2" Vector__XXX
 SG_ CAN_TX_TRACK_RANGE : 18|11@0+ (0.1,0) [0|204.7] "m" Vector__XXX
 SG_ CAN_TX_TRACK_ONCOMING : 0|1@0+ (1,0) [0|1] "" Vector__XXX
 SG_ CAN_TX_TRACK_MED_RANGE_MODE : 55|2@0+ (1,0) [0|3] "" Vector__XXX
 SG_ CAN_TX_TRACK_LAT_RATE : 7|6@0- (0.25,0) [-8|7.75] "" Vector__XXX
 SG_ CAN_TX_TRACK_GROUPING_CHANGED : 1|1@0+ (1,0) [0|1] "" Vector__XXX
 SG_ CAN_TX_TRACK_BRIDGE_OBJECT : 39|1@0+ (1,0) [0|1] "" Vector__XXX
 SG_ CAN_TX_TRACK_ANGLE : 12|10@0- (0.1,0) [-51.2|51.1] "" Vector__XXX

BO_ 1310 Target31: 8 Vector__XXX
 SG_ CAN_TX_TRACK_WIDTH : 37|4@0+ (0.5,0) [0|7.5] "" Vector__XXX
 SG_ CAN_TX_TRACK_STATUS : 15|3@0+ (1,0) [0|7] "" Vector__XXX
 SG_ CAN_TX_TRACK_ROLLING_COUNT : 38|1@0+ (1,0) [0|1] "" Vector__XXX
 SG_ CAN_TX_TRACK_RANGE_RATE : 53|14@0- (0.01,0) [-81.92|81.91] "m/s" Vector__XXX
 SG_ CAN_TX_TRACK_RANGE_ACCEL : 33|10@0- (0.05,0) [-25.6|25.55] "m/s^2" Vector__XXX
 SG_ CAN_TX_TRACK_RANGE : 18|11@0+ (0.1,0) [0|204.7] "m" Vector__XXX
 SG_ CAN_TX_TRACK_ONCOMING : 0|1@0+ (1,0) [0|1] "" Vector__XXX
 SG_ CAN_TX_TRACK_MED_RANGE_MODE : 55|2@0+ (1,0) [0|3] "" Vector__XXX
 SG_ CAN_TX_TRACK_LAT_RATE : 7|6@0- (0.25,0) [-8|7.75] "" Vector__XXX
 SG_ CAN_TX_TRACK_GROUPING_CHANGED : 1|1@0+ (1,0) [0|1] "" Vector__XXX
 SG_ CAN_TX_TRACK_BRIDGE_OBJECT : 39|1@0+ (1,0) [0|1] "" Vector__XXX
 SG_ CAN_TX_TRACK_ANGLE : 12|10@0- (0.1,0) [-51.2|51.1] "" Vector__XXX

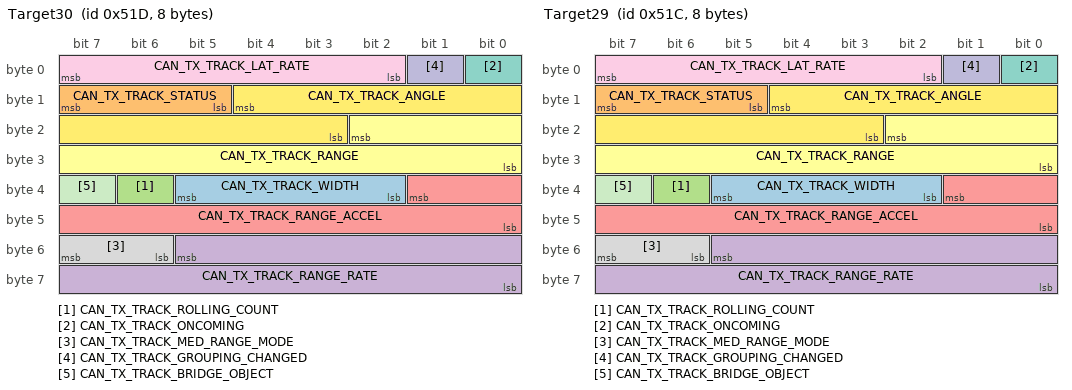
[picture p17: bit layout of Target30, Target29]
BO_ 1309 Target30: 8 Vector__XXX
 SG_ CAN_TX_TRACK_WIDTH : 37|4@0+ (0.5,0) [0|7.5] "" Vector__XXX
 SG_ CAN_TX_TRACK_STATUS : 15|3@0+ (1,0) [0|7] "" Vector__XXX
 SG_ CAN_TX_TRACK_ROLLING_COUNT : 38|1@0+ (1,0) [0|1] "" Vector__XXX
 SG_ CAN_TX_TRACK_RANGE_RATE : 53|14@0- (0.01,0) [-81.92|81.91] "m/s" Vector__XXX
 SG_ CAN_TX_TRACK_RANGE_ACCEL : 33|10@0- (0.05,0) [-25.6|25.55] "m/s^2" Vector__XXX
 SG_ CAN_TX_TRACK_RANGE : 18|11@0+ (0.1,0) [0|204.7] "m" Vector__XXX
 SG_ CAN_TX_TRACK_ONCOMING : 0|1@0+ (1,0) [0|1] "" Vector__XXX
 SG_ CAN_TX_TRACK_MED_RANGE_MODE : 55|2@0+ (1,0) [0|3] "" Vector__XXX
 SG_ CAN_TX_TRACK_LAT_RATE : 7|6@0- (0.25,0) [-8|7.75] "" Vector__XXX
 SG_ CAN_TX_TRACK_GROUPING_CHANGED : 1|1@0+ (1,0) [0|1] "" Vector__XXX
 SG_ CAN_TX_TRACK_BRIDGE_OBJECT : 39|1@0+ (1,0) [0|1] "" Vector__XXX
 SG_ CAN_TX_TRACK_ANGLE : 12|10@0- (0.1,0) [-51.2|51.1] "" Vector__XXX

BO_ 1308 Target29: 8 Vector__XXX
 SG_ CAN_TX_TRACK_WIDTH : 37|4@0+ (0.5,0) [0|7.5] "" Vector__XXX
 SG_ CAN_TX_TRACK_STATUS : 15|3@0+ (1,0) [0|7] "" Vector__XXX
 SG_ CAN_TX_TRACK_ROLLING_COUNT : 38|1@0+ (1,0) [0|1] "" Vector__XXX
 SG_ CAN_TX_TRACK_RANGE_RATE : 53|14@0- (0.01,0) [-81.92|81.91] "m/s" Vector__XXX
 SG_ CAN_TX_TRACK_RANGE_ACCEL : 33|10@0- (0.05,0) [-25.6|25.55] "m/s^2" Vector__XXX
 SG_ CAN_TX_TRACK_RANGE : 18|11@0+ (0.1,0) [0|204.7] "m" Vector__XXX
 SG_ CAN_TX_TRACK_ONCOMING : 0|1@0+ (1,0) [0|1] "" Vector__XXX
 SG_ CAN_TX_TRACK_MED_RANGE_MODE : 55|2@0+ (1,0) [0|3] "" Vector__XXX
 SG_ CAN_TX_TRACK_LAT_RATE : 7|6@0- (0.25,0) [-8|7.75] "" Vector__XXX
 SG_ CAN_TX_TRACK_GROUPING_CHANGED : 1|1@0+ (1,0) [0|1] "" Vector__XXX
 SG_ CAN_TX_TRACK_BRIDGE_OBJECT : 39|1@0+ (1,0) [0|1] "" Vector__XXX
 SG_ CAN_TX_TRACK_ANGLE : 12|10@0- (0.1,0) [-51.2|51.1] "" Vector__XXX

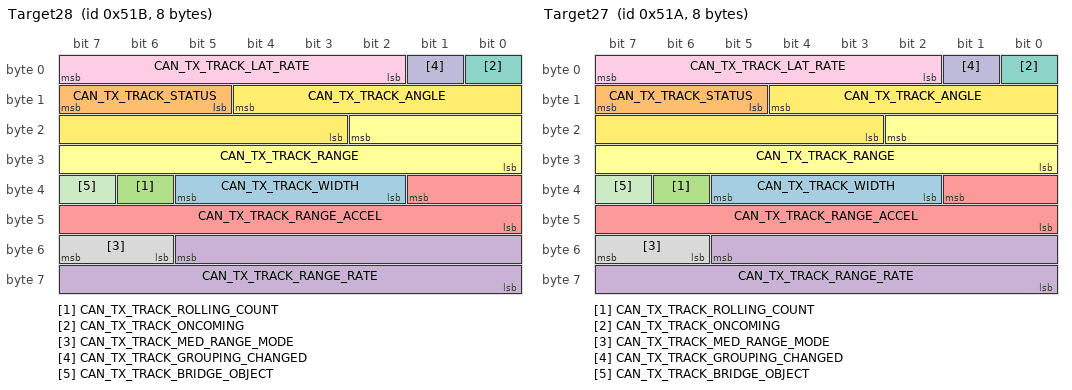
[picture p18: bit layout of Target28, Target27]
BO_ 1307 Target28: 8 Vector__XXX
 SG_ CAN_TX_TRACK_WIDTH : 37|4@0+ (0.5,0) [0|7.5] "" Vector__XXX
 SG_ CAN_TX_TRACK_STATUS : 15|3@0+ (1,0) [0|7] "" Vector__XXX
 SG_ CAN_TX_TRACK_ROLLING_COUNT : 38|1@0+ (1,0) [0|1] "" Vector__XXX
 SG_ CAN_TX_TRACK_RANGE_RATE : 53|14@0- (0.01,0) [-81.92|81.91] "m/s" Vector__XXX
 SG_ CAN_TX_TRACK_RANGE_ACCEL : 33|10@0- (0.05,0) [-25.6|25.55] "m/s^2" Vector__XXX
 SG_ CAN_TX_TRACK_RANGE : 18|11@0+ (0.1,0) [0|204.7] "m" Vector__XXX
 SG_ CAN_TX_TRACK_ONCOMING : 0|1@0+ (1,0) [0|1] "" Vector__XXX
 SG_ CAN_TX_TRACK_MED_RANGE_MODE : 55|2@0+ (1,0) [0|3] "" Vector__XXX
 SG_ CAN_TX_TRACK_LAT_RATE : 7|6@0- (0.25,0) [-8|7.75] "" Vector__XXX
 SG_ CAN_TX_TRACK_GROUPING_CHANGED : 1|1@0+ (1,0) [0|1] "" Vector__XXX
 SG_ CAN_TX_TRACK_BRIDGE_OBJECT : 39|1@0+ (1,0) [0|1] "" Vector__XXX
 SG_ CAN_TX_TRACK_ANGLE : 12|10@0- (0.1,0) [-51.2|51.1] "" Vector__XXX

BO_ 1306 Target27: 8 Vector__XXX
 SG_ CAN_TX_TRACK_WIDTH : 37|4@0+ (0.5,0) [0|7.5] "" Vector__XXX
 SG_ CAN_TX_TRACK_STATUS : 15|3@0+ (1,0) [0|7] "" Vector__XXX
 SG_ CAN_TX_TRACK_ROLLING_COUNT : 38|1@0+ (1,0) [0|1] "" Vector__XXX
 SG_ CAN_TX_TRACK_RANGE_RATE : 53|14@0- (0.01,0) [-81.92|81.91] "m/s" Vector__XXX
 SG_ CAN_TX_TRACK_RANGE_ACCEL : 33|10@0- (0.05,0) [-25.6|25.55] "m/s^2" Vector__XXX
 SG_ CAN_TX_TRACK_RANGE : 18|11@0+ (0.1,0) [0|204.7] "m" Vector__XXX
 SG_ CAN_TX_TRACK_ONCOMING : 0|1@0+ (1,0) [0|1] "" Vector__XXX
 SG_ CAN_TX_TRACK_MED_RANGE_MODE : 55|2@0+ (1,0) [0|3] "" Vector__XXX
 SG_ CAN_TX_TRACK_LAT_RATE : 7|6@0- (0.25,0) [-8|7.75] "" Vector__XXX
 SG_ CAN_TX_TRACK_GROUPING_CHANGED : 1|1@0+ (1,0) [0|1] "" Vector__XXX
 SG_ CAN_TX_TRACK_BRIDGE_OBJECT : 39|1@0+ (1,0) [0|1] "" Vector__XXX
 SG_ CAN_TX_TRACK_ANGLE : 12|10@0- (0.1,0) [-51.2|51.1] "" Vector__XXX

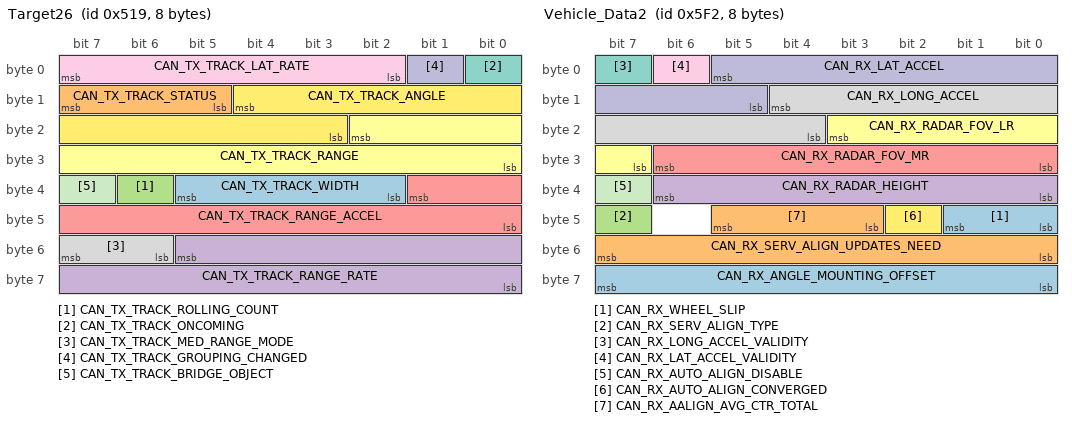
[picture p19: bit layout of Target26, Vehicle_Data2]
BO_ 1305 Target26: 8 Vector__XXX
 SG_ CAN_TX_TRACK_WIDTH : 37|4@0+ (0.5,0) [0|7.5] "" Vector__XXX
 SG_ CAN_TX_TRACK_STATUS : 15|3@0+ (1,0) [0|7] "" Vector__XXX
 SG_ CAN_TX_TRACK_ROLLING_COUNT : 38|1@0+ (1,0) [0|1] "" Vector__XXX
 SG_ CAN_TX_TRACK_RANGE_RATE : 53|14@0- (0.01,0) [-81.92|81.91] "m/s" Vector__XXX
 SG_ CAN_TX_TRACK_RANGE_ACCEL : 33|10@0- (0.05,0) [-25.6|25.55] "m/s^2" Vector__XXX
 SG_ CAN_TX_TRACK_RANGE : 18|11@0+ (0.1,0) [0|204.7] "m" Vector__XXX
 SG_ CAN_TX_TRACK_ONCOMING : 0|1@0+ (1,0) [0|1] "" Vector__XXX
 SG_ CAN_TX_TRACK_MED_RANGE_MODE : 55|2@0+ (1,0) [0|3] "" Vector__XXX
 SG_ CAN_TX_TRACK_LAT_RATE : 7|6@0- (0.25,0) [-8|7.75] "" Vector__XXX
 SG_ CAN_TX_TRACK_GROUPING_CHANGED : 1|1@0+ (1,0) [0|1] "" Vector__XXX
 SG_ CAN_TX_TRACK_BRIDGE_OBJECT : 39|1@0+ (1,0) [0|1] "" Vector__XXX
 SG_ CAN_TX_TRACK_ANGLE : 12|10@0- (0.1,0) [-51.2|51.1] "" Vector__XXX

BO_ 1304 Target25: 8 Vector__XXX
 SG_ CAN_TX_TRACK_WIDTH : 37|4@0+ (0.5,0) [0|7.5] "" Vector__XXX
 SG_ CAN_TX_TRACK_STATUS : 15|3@0+ (1,0) [0|7] "" Vector__XXX
 SG_ CAN_TX_TRACK_ROLLING_COUNT : 38|1@0+ (1,0) [0|1] "" Vector__XXX
 SG_ CAN_TX_TRACK_RANGE_RATE : 53|14@0- (0.01,0) [-81.92|81.91] "m/s" Vector__XXX
 SG_ CAN_TX_TRACK_RANGE_ACCEL : 33|10@0- (0.05,0) [-25.6|25.55] "m/s^2" Vector__XXX
 SG_ CAN_TX_TRACK_RANGE : 18|11@0+ (0.1,0) [0|204.7] "m" Vector__XXX
 SG_ CAN_TX_TRACK_ONCOMING : 0|1@0+ (1,0) [0|1] "" Vector__XXX
 SG_ CAN_TX_TRACK_MED_RANGE_MODE : 55|2@0+ (1,0) [0|3] "" Vector__XXX
 SG_ CAN_TX_TRACK_LAT_RATE : 7|6@0- (0.25,0) [-8|7.75] "" Vector__XXX
 SG_ CAN_TX_TRACK_GROUPING_CHANGED : 1|1@0+ (1,0) [0|1] "" Vector__XXX
 SG_ CAN_TX_TRACK_BRIDGE_OBJECT : 39|1@0+ (1,0) [0|1] "" Vector__XXX
 SG_ CAN_TX_TRACK_ANGLE : 12|10@0- (0.1,0) [-51.2|51.1] "" Vector__XXX

BO_ 1303 Target24: 8 Vector__XXX
 SG_ CAN_TX_TRACK_WIDTH : 37|4@0+ (0.5,0) [0|7.5] "" Vector__XXX
 SG_ CAN_TX_TRACK_STATUS : 15|3@0+ (1,0) [0|7] "" Vector__XXX
 SG_ CAN_TX_TRACK_ROLLING_COUNT : 38|1@0+ (1,0) [0|1] "" Vector__XXX
 SG_ CAN_TX_TRACK_RANGE_RATE : 53|14@0- (0.01,0) [-81.92|81.91] "m/s" Vector__XXX
 SG_ CAN_TX_TRACK_RANGE_ACCEL : 33|10@0- (0.05,0) [-25.6|25.55] "m/s^2" Vector__XXX
 SG_ CAN_TX_TRACK_RANGE : 18|11@0+ (0.1,0) [0|204.7] "m" Vector__XXX
 SG_ CAN_TX_TRACK_ONCOMING : 0|1@0+ (1,0) [0|1] "" Vector__XXX
 SG_ CAN_TX_TRACK_MED_RANGE_MODE : 55|2@0+ (1,0) [0|3] "" Vector__XXX
 SG_ CAN_TX_TRACK_LAT_RATE : 7|6@0- (0.25,0) [-8|7.75] "" Vector__XXX
 SG_ CAN_TX_TRACK_GROUPING_CHANGED : 1|1@0+ (1,0) [0|1] "" Vector__XXX
 SG_ CAN_TX_TRACK_BRIDGE_OBJECT : 39|1@0+ (1,0) [0|1] "" Vector__XXX
 SG_ CAN_TX_TRACK_ANGLE : 12|10@0- (0.1,0) [-51.2|51.1] "" Vector__XXX

BO_ 1302 Target23: 8 Vector__XXX
 SG_ CAN_TX_TRACK_WIDTH : 37|4@0+ (0.5,0) [0|7.5] "" Vector__XXX
 SG_ CAN_TX_TRACK_STATUS : 15|3@0+ (1,0) [0|7] "" Vector__XXX
 SG_ CAN_TX_TRACK_ROLLING_COUNT : 38|1@0+ (1,0) [0|1] "" Vector__XXX
 SG_ CAN_TX_TRACK_RANGE_RATE : 53|14@0- (0.01,0) [-81.92|81.91] "m/s" Vector__XXX
 SG_ CAN_TX_TRACK_RANGE_ACCEL : 33|10@0- (0.05,0) [-25.6|25.55] "m/s^2" Vector__XXX
 SG_ CAN_TX_TRACK_RANGE : 18|11@0+ (0.1,0) [0|204.7] "m" Vector__XXX
 SG_ CAN_TX_TRACK_ONCOMING : 0|1@0+ (1,0) [0|1] "" Vector__XXX
 SG_ CAN_TX_TRACK_MED_RANGE_MODE : 55|2@0+ (1,0) [0|3] "" Vector__XXX
 SG_ CAN_TX_TRACK_LAT_RATE : 7|6@0- (0.25,0) [-8|7.75] "" Vector__XXX
 SG_ CAN_TX_TRACK_GROUPING_CHANGED : 1|1@0+ (1,0) [0|1] "" Vector__XXX
 SG_ CAN_TX_TRACK_BRIDGE_OBJECT : 39|1@0+ (1,0) [0|1] "" Vector__XXX
 SG_ CAN_TX_TRACK_ANGLE : 12|10@0- (0.1,0) [-51.2|51.1] "" Vector__XXX

BO_ 1301 Target22: 8 Vector__XXX
 SG_ CAN_TX_TRACK_WIDTH : 37|4@0+ (0.5,0) [0|7.5] "" Vector__XXX
 SG_ CAN_TX_TRACK_STATUS : 15|3@0+ (1,0) [0|7] "" Vector__XXX
 SG_ CAN_TX_TRACK_ROLLING_COUNT : 38|1@0+ (1,0) [0|1] "" Vector__XXX
 SG_ CAN_TX_TRACK_RANGE_RATE : 53|14@0- (0.01,0) [-81.92|81.91] "m/s" Vector__XXX
 SG_ CAN_TX_TRACK_RANGE_ACCEL : 33|10@0- (0.05,0) [-25.6|25.55] "m/s^2" Vector__XXX
 SG_ CAN_TX_TRACK_RANGE : 18|11@0+ (0.1,0) [0|204.7] "m" Vector__XXX
 SG_ CAN_TX_TRACK_ONCOMING : 0|1@0+ (1,0) [0|1] "" Vector__XXX
 SG_ CAN_TX_TRACK_MED_RANGE_MODE : 55|2@0+ (1,0) [0|3] "" Vector__XXX
 SG_ CAN_TX_TRACK_LAT_RATE : 7|6@0- (0.25,0) [-8|7.75] "" Vector__XXX
 SG_ CAN_TX_TRACK_GROUPING_CHANGED : 1|1@0+ (1,0) [0|1] "" Vector__XXX
 SG_ CAN_TX_TRACK_BRIDGE_OBJECT : 39|1@0+ (1,0) [0|1] "" Vector__XXX
 SG_ CAN_TX_TRACK_ANGLE : 12|10@0- (0.1,0) [-51.2|51.1] "" Vector__XXX

BO_ 1300 Target21: 8 Vector__XXX
 SG_ CAN_TX_TRACK_WIDTH : 37|4@0+ (0.5,0) [0|7.5] "" Vector__XXX
 SG_ CAN_TX_TRACK_STATUS : 15|3@0+ (1,0) [0|7] "" Vector__XXX
 SG_ CAN_TX_TRACK_ROLLING_COUNT : 38|1@0+ (1,0) [0|1] "" Vector__XXX
 SG_ CAN_TX_TRACK_RANGE_RATE : 53|14@0- (0.01,0) [-81.92|81.91] "m/s" Vector__XXX
 SG_ CAN_TX_TRACK_RANGE_ACCEL : 33|10@0- (0.05,0) [-25.6|25.55] "m/s^2" Vector__XXX
 SG_ CAN_TX_TRACK_RANGE : 18|11@0+ (0.1,0) [0|204.7] "m" Vector__XXX
 SG_ CAN_TX_TRACK_ONCOMING : 0|1@0+ (1,0) [0|1] "" Vector__XXX
 SG_ CAN_TX_TRACK_MED_RANGE_MODE : 55|2@0+ (1,0) [0|3] "" Vector__XXX
 SG_ CAN_TX_TRACK_LAT_RATE : 7|6@0- (0.25,0) [-8|7.75] "" Vector__XXX
 SG_ CAN_TX_TRACK_GROUPING_CHANGED : 1|1@0+ (1,0) [0|1] "" Vector__XXX
 SG_ CAN_TX_TRACK_BRIDGE_OBJECT : 39|1@0+ (1,0) [0|1] "" Vector__XXX
 SG_ CAN_TX_TRACK_ANGLE : 12|10@0- (0.1,0) [-51.2|51.1] "" Vector__XXX

BO_ 1299 Target20: 8 Vector__XXX
 SG_ CAN_TX_TRACK_WIDTH : 37|4@0+ (0.5,0) [0|7.5] "" Vector__XXX
 SG_ CAN_TX_TRACK_STATUS : 15|3@0+ (1,0) [0|7] "" Vector__XXX
 SG_ CAN_TX_TRACK_ROLLING_COUNT : 38|1@0+ (1,0) [0|1] "" Vector__XXX
 SG_ CAN_TX_TRACK_RANGE_RATE : 53|14@0- (0.01,0) [-81.92|81.91] "m/s" Vector__XXX
 SG_ CAN_TX_TRACK_RANGE_ACCEL : 33|10@0- (0.05,0) [-25.6|25.55] "m/s^2" Vector__XXX
 SG_ CAN_TX_TRACK_RANGE : 18|11@0+ (0.1,0) [0|204.7] "m" Vector__XXX
 SG_ CAN_TX_TRACK_ONCOMING : 0|1@0+ (1,0) [0|1] "" Vector__XXX
 SG_ CAN_TX_TRACK_MED_RANGE_MODE : 55|2@0+ (1,0) [0|3] "" Vector__XXX
 SG_ CAN_TX_TRACK_LAT_RATE : 7|6@0- (0.25,0) [-8|7.75] "" Vector__XXX
 SG_ CAN_TX_TRACK_GROUPING_CHANGED : 1|1@0+ (1,0) [0|1] "" Vector__XXX
 SG_ CAN_TX_TRACK_BRIDGE_OBJECT : 39|1@0+ (1,0) [0|1] "" Vector__XXX
 SG_ CAN_TX_TRACK_ANGLE : 12|10@0- (0.1,0) [-51.2|51.1] "" Vector__XXX

BO_ 1298 Target19: 8 Vector__XXX
 SG_ CAN_TX_TRACK_WIDTH : 37|4@0+ (0.5,0) [0|7.5] "" Vector__XXX
 SG_ CAN_TX_TRACK_STATUS : 15|3@0+ (1,0) [0|7] "" Vector__XXX
 SG_ CAN_TX_TRACK_ROLLING_COUNT : 38|1@0+ (1,0) [0|1] "" Vector__XXX
 SG_ CAN_TX_TRACK_RANGE_RATE : 53|14@0- (0.01,0) [-81.92|81.91] "m/s" Vector__XXX
 SG_ CAN_TX_TRACK_RANGE_ACCEL : 33|10@0- (0.05,0) [-25.6|25.55] "m/s^2" Vector__XXX
 SG_ CAN_TX_TRACK_RANGE : 18|11@0+ (0.1,0) [0|204.7] "m" Vector__XXX
 SG_ CAN_TX_TRACK_ONCOMING : 0|1@0+ (1,0) [0|1] "" Vector__XXX
 SG_ CAN_TX_TRACK_MED_RANGE_MODE : 55|2@0+ (1,0) [0|3] "" Vector__XXX
 SG_ CAN_TX_TRACK_LAT_RATE : 7|6@0- (0.25,0) [-8|7.75] "" Vector__XXX
 SG_ CAN_TX_TRACK_GROUPING_CHANGED : 1|1@0+ (1,0) [0|1] "" Vector__XXX
 SG_ CAN_TX_TRACK_BRIDGE_OBJECT : 39|1@0+ (1,0) [0|1] "" Vector__XXX
 SG_ CAN_TX_TRACK_ANGLE : 12|10@0- (0.1,0) [-51.2|51.1] "" Vector__XXX

BO_ 1297 Target18: 8 Vector__XXX
 SG_ CAN_TX_TRACK_WIDTH : 37|4@0+ (0.5,0) [0|7.5] "" Vector__XXX
 SG_ CAN_TX_TRACK_STATUS : 15|3@0+ (1,0) [0|7] "" Vector__XXX
 SG_ CAN_TX_TRACK_ROLLING_COUNT : 38|1@0+ (1,0) [0|1] "" Vector__XXX
 SG_ CAN_TX_TRACK_RANGE_RATE : 53|14@0- (0.01,0) [-81.92|81.91] "m/s" Vector__XXX
 SG_ CAN_TX_TRACK_RANGE_ACCEL : 33|10@0- (0.05,0) [-25.6|25.55] "m/s^2" Vector__XXX
 SG_ CAN_TX_TRACK_RANGE : 18|11@0+ (0.1,0) [0|204.7] "m" Vector__XXX
 SG_ CAN_TX_TRACK_ONCOMING : 0|1@0+ (1,0) [0|1] "" Vector__XXX
 SG_ CAN_TX_TRACK_MED_RANGE_MODE : 55|2@0+ (1,0) [0|3] "" Vector__XXX
 SG_ CAN_TX_TRACK_LAT_RATE : 7|6@0- (0.25,0) [-8|7.75] "" Vector__XXX
 SG_ CAN_TX_TRACK_GROUPING_CHANGED : 1|1@0+ (1,0) [0|1] "" Vector__XXX
 SG_ CAN_TX_TRACK_BRIDGE_OBJECT : 39|1@0+ (1,0) [0|1] "" Vector__XXX
 SG_ CAN_TX_TRACK_ANGLE : 12|10@0- (0.1,0) [-51.2|51.1] "" Vector__XXX

BO_ 1296 Target17: 8 Vector__XXX
 SG_ CAN_TX_TRACK_WIDTH : 37|4@0+ (0.5,0) [0|7.5] "" Vector__XXX
 SG_ CAN_TX_TRACK_STATUS : 15|3@0+ (1,0) [0|7] "" Vector__XXX
 SG_ CAN_TX_TRACK_ROLLING_COUNT : 38|1@0+ (1,0) [0|1] "" Vector__XXX
 SG_ CAN_TX_TRACK_RANGE_RATE : 53|14@0- (0.01,0) [-81.92|81.91] "m/s" Vector__XXX
 SG_ CAN_TX_TRACK_RANGE_ACCEL : 33|10@0- (0.05,0) [-25.6|25.55] "m/s^2" Vector__XXX
 SG_ CAN_TX_TRACK_RANGE : 18|11@0+ (0.1,0) [0|204.7] "m" Vector__XXX
 SG_ CAN_TX_TRACK_ONCOMING : 0|1@0+ (1,0) [0|1] "" Vector__XXX
 SG_ CAN_TX_TRACK_MED_RANGE_MODE : 55|2@0+ (1,0) [0|3] "" Vector__XXX
 SG_ CAN_TX_TRACK_LAT_RATE : 7|6@0- (0.25,0) [-8|7.75] "" Vector__XXX
 SG_ CAN_TX_TRACK_GROUPING_CHANGED : 1|1@0+ (1,0) [0|1] "" Vector__XXX
 SG_ CAN_TX_TRACK_BRIDGE_OBJECT : 39|1@0+ (1,0) [0|1] "" Vector__XXX
 SG_ CAN_TX_TRACK_ANGLE : 12|10@0- (0.1,0) [-51.2|51.1] "" Vector__XXX

BO_ 1295 Target16: 8 Vector__XXX
 SG_ CAN_TX_TRACK_WIDTH : 37|4@0+ (0.5,0) [0|7.5] "" Vector__XXX
 SG_ CAN_TX_TRACK_STATUS : 15|3@0+ (1,0) [0|7] "" Vector__XXX
 SG_ CAN_TX_TRACK_ROLLING_COUNT : 38|1@0+ (1,0) [0|1] "" Vector__XXX
 SG_ CAN_TX_TRACK_RANGE_RATE : 53|14@0- (0.01,0) [-81.92|81.91] "m/s" Vector__XXX
 SG_ CAN_TX_TRACK_RANGE_ACCEL : 33|10@0- (0.05,0) [-25.6|25.55] "m/s^2" Vector__XXX
 SG_ CAN_TX_TRACK_RANGE : 18|11@0+ (0.1,0) [0|204.7] "m" Vector__XXX
 SG_ CAN_TX_TRACK_ONCOMING : 0|1@0+ (1,0) [0|1] "" Vector__XXX
 SG_ CAN_TX_TRACK_MED_RANGE_MODE : 55|2@0+ (1,0) [0|3] "" Vector__XXX
 SG_ CAN_TX_TRACK_LAT_RATE : 7|6@0- (0.25,0) [-8|7.75] "" Vector__XXX
 SG_ CAN_TX_TRACK_GROUPING_CHANGED : 1|1@0+ (1,0) [0|1] "" Vector__XXX
 SG_ CAN_TX_TRACK_BRIDGE_OBJECT : 39|1@0+ (1,0) [0|1] "" Vector__XXX
 SG_ CAN_TX_TRACK_ANGLE : 12|10@0- (0.1,0) [-51.2|51.1] "" Vector__XXX

BO_ 1294 Target15: 8 Vector__XXX
 SG_ CAN_TX_TRACK_WIDTH : 37|4@0+ (0.5,0) [0|7.5] "" Vector__XXX
 SG_ CAN_TX_TRACK_STATUS : 15|3@0+ (1,0) [0|7] "" Vector__XXX
 SG_ CAN_TX_TRACK_ROLLING_COUNT : 38|1@0+ (1,0) [0|1] "" Vector__XXX
 SG_ CAN_TX_TRACK_RANGE_RATE : 53|14@0- (0.01,0) [-81.92|81.91] "m/s" Vector__XXX
 SG_ CAN_TX_TRACK_RANGE_ACCEL : 33|10@0- (0.05,0) [-25.6|25.55] "m/s^2" Vector__XXX
 SG_ CAN_TX_TRACK_RANGE : 18|11@0+ (0.1,0) [0|204.7] "m" Vector__XXX
 SG_ CAN_TX_TRACK_ONCOMING : 0|1@0+ (1,0) [0|1] "" Vector__XXX
 SG_ CAN_TX_TRACK_MED_RANGE_MODE : 55|2@0+ (1,0) [0|3] "" Vector__XXX
 SG_ CAN_TX_TRACK_LAT_RATE : 7|6@0- (0.25,0) [-8|7.75] "" Vector__XXX
 SG_ CAN_TX_TRACK_GROUPING_CHANGED : 1|1@0+ (1,0) [0|1] "" Vector__XXX
 SG_ CAN_TX_TRACK_BRIDGE_OBJECT : 39|1@0+ (1,0) [0|1] "" Vector__XXX
 SG_ CAN_TX_TRACK_ANGLE : 12|10@0- (0.1,0) [-51.2|51.1] "" Vector__XXX

BO_ 1293 Target14: 8 Vector__XXX
 SG_ CAN_TX_TRACK_WIDTH : 37|4@0+ (0.5,0) [0|7.5] "" Vector__XXX
 SG_ CAN_TX_TRACK_STATUS : 15|3@0+ (1,0) [0|7] "" Vector__XXX
 SG_ CAN_TX_TRACK_ROLLING_COUNT : 38|1@0+ (1,0) [0|1] "" Vector__XXX
 SG_ CAN_TX_TRACK_RANGE_RATE : 53|14@0- (0.01,0) [-81.92|81.91] "m/s" Vector__XXX
 SG_ CAN_TX_TRACK_RANGE_ACCEL : 33|10@0- (0.05,0) [-25.6|25.55] "m/s^2" Vector__XXX
 SG_ CAN_TX_TRACK_RANGE : 18|11@0+ (0.1,0) [0|204.7] "m" Vector__XXX
 SG_ CAN_TX_TRACK_ONCOMING : 0|1@0+ (1,0) [0|1] "" Vector__XXX
 SG_ CAN_TX_TRACK_MED_RANGE_MODE : 55|2@0+ (1,0) [0|3] "" Vector__XXX
 SG_ CAN_TX_TRACK_LAT_RATE : 7|6@0- (0.25,0) [-8|7.75] "" Vector__XXX
 SG_ CAN_TX_TRACK_GROUPING_CHANGED : 1|1@0+ (1,0) [0|1] "" Vector__XXX
 SG_ CAN_TX_TRACK_BRIDGE_OBJECT : 39|1@0+ (1,0) [0|1] "" Vector__XXX
 SG_ CAN_TX_TRACK_ANGLE : 12|10@0- (0.1,0) [-51.2|51.1] "" Vector__XXX

BO_ 1292 Target13: 8 Vector__XXX
 SG_ CAN_TX_TRACK_WIDTH : 37|4@0+ (0.5,0) [0|7.5] "" Vector__XXX
 SG_ CAN_TX_TRACK_STATUS : 15|3@0+ (1,0) [0|7] "" Vector__XXX
 SG_ CAN_TX_TRACK_ROLLING_COUNT : 38|1@0+ (1,0) [0|1] "" Vector__XXX
 SG_ CAN_TX_TRACK_RANGE_RATE : 53|14@0- (0.01,0) [-81.92|81.91] "m/s" Vector__XXX
 SG_ CAN_TX_TRACK_RANGE_ACCEL : 33|10@0- (0.05,0) [-25.6|25.55] "m/s^2" Vector__XXX
 SG_ CAN_TX_TRACK_RANGE : 18|11@0+ (0.1,0) [0|204.7] "m" Vector__XXX
 SG_ CAN_TX_TRACK_ONCOMING : 0|1@0+ (1,0) [0|1] "" Vector__XXX
 SG_ CAN_TX_TRACK_MED_RANGE_MODE : 55|2@0+ (1,0) [0|3] "" Vector__XXX
 SG_ CAN_TX_TRACK_LAT_RATE : 7|6@0- (0.25,0) [-8|7.75] "" Vector__XXX
 SG_ CAN_TX_TRACK_GROUPING_CHANGED : 1|1@0+ (1,0) [0|1] "" Vector__XXX
 SG_ CAN_TX_TRACK_BRIDGE_OBJECT : 39|1@0+ (1,0) [0|1] "" Vector__XXX
 SG_ CAN_TX_TRACK_ANGLE : 12|10@0- (0.1,0) [-51.2|51.1] "" Vector__XXX

BO_ 1291 Target12: 8 Vector__XXX
 SG_ CAN_TX_TRACK_WIDTH : 37|4@0+ (0.5,0) [0|7.5] "" Vector__XXX
 SG_ CAN_TX_TRACK_STATUS : 15|3@0+ (1,0) [0|7] "" Vector__XXX
 SG_ CAN_TX_TRACK_ROLLING_COUNT : 38|1@0+ (1,0) [0|1] "" Vector__XXX
 SG_ CAN_TX_TRACK_RANGE_RATE : 53|14@0- (0.01,0) [-81.92|81.91] "m/s" Vector__XXX
 SG_ CAN_TX_TRACK_RANGE_ACCEL : 33|10@0- (0.05,0) [-25.6|25.55] "m/s^2" Vector__XXX
 SG_ CAN_TX_TRACK_RANGE : 18|11@0+ (0.1,0) [0|204.7] "m" Vector__XXX
 SG_ CAN_TX_TRACK_ONCOMING : 0|1@0+ (1,0) [0|1] "" Vector__XXX
 SG_ CAN_TX_TRACK_MED_RANGE_MODE : 55|2@0+ (1,0) [0|3] "" Vector__XXX
 SG_ CAN_TX_TRACK_LAT_RATE : 7|6@0- (0.25,0) [-8|7.75] "" Vector__XXX
 SG_ CAN_TX_TRACK_GROUPING_CHANGED : 1|1@0+ (1,0) [0|1] "" Vector__XXX
 SG_ CAN_TX_TRACK_BRIDGE_OBJECT : 39|1@0+ (1,0) [0|1] "" Vector__XXX
 SG_ CAN_TX_TRACK_ANGLE : 12|10@0- (0.1,0) [-51.2|51.1] "" Vector__XXX

BO_ 1290 Target11: 8 Vector__XXX
 SG_ CAN_TX_TRACK_WIDTH : 37|4@0+ (0.5,0) [0|7.5] "" Vector__XXX
 SG_ CAN_TX_TRACK_STATUS : 15|3@0+ (1,0) [0|7] "" Vector__XXX
 SG_ CAN_TX_TRACK_ROLLING_COUNT : 38|1@0+ (1,0) [0|1] "" Vector__XXX
 SG_ CAN_TX_TRACK_RANGE_RATE : 53|14@0- (0.01,0) [-81.92|81.91] "m/s" Vector__XXX
 SG_ CAN_TX_TRACK_RANGE_ACCEL : 33|10@0- (0.05,0) [-25.6|25.55] "m/s^2" Vector__XXX
 SG_ CAN_TX_TRACK_RANGE : 18|11@0+ (0.1,0) [0|204.7] "m" Vector__XXX
 SG_ CAN_TX_TRACK_ONCOMING : 0|1@0+ (1,0) [0|1] "" Vector__XXX
 SG_ CAN_TX_TRACK_MED_RANGE_MODE : 55|2@0+ (1,0) [0|3] "" Vector__XXX
 SG_ CAN_TX_TRACK_LAT_RATE : 7|6@0- (0.25,0) [-8|7.75] "" Vector__XXX
 SG_ CAN_TX_TRACK_GROUPING_CHANGED : 1|1@0+ (1,0) [0|1] "" Vector__XXX
 SG_ CAN_TX_TRACK_BRIDGE_OBJECT : 39|1@0+ (1,0) [0|1] "" Vector__XXX
 SG_ CAN_TX_TRACK_ANGLE : 12|10@0- (0.1,0) [-51.2|51.1] "" Vector__XXX

BO_ 1289 Target10: 8 Vector__XXX
 SG_ CAN_TX_TRACK_WIDTH : 37|4@0+ (0.5,0) [0|7.5] "" Vector__XXX
 SG_ CAN_TX_TRACK_STATUS : 15|3@0+ (1,0) [0|7] "" Vector__XXX
 SG_ CAN_TX_TRACK_ROLLING_COUNT : 38|1@0+ (1,0) [0|1] "" Vector__XXX
 SG_ CAN_TX_TRACK_RANGE_RATE : 53|14@0- (0.01,0) [-81.92|81.91] "m/s" Vector__XXX
 SG_ CAN_TX_TRACK_RANGE_ACCEL : 33|10@0- (0.05,0) [-25.6|25.55] "m/s^2" Vector__XXX
 SG_ CAN_TX_TRACK_RANGE : 18|11@0+ (0.1,0) [0|204.7] "m" Vector__XXX
 SG_ CAN_TX_TRACK_ONCOMING : 0|1@0+ (1,0) [0|1] "" Vector__XXX
 SG_ CAN_TX_TRACK_MED_RANGE_MODE : 55|2@0+ (1,0) [0|3] "" Vector__XXX
 SG_ CAN_TX_TRACK_LAT_RATE : 7|6@0- (0.25,0) [-8|7.75] "" Vector__XXX
 SG_ CAN_TX_TRACK_GROUPING_CHANGED : 1|1@0+ (1,0) [0|1] "" Vector__XXX
 SG_ CAN_TX_TRACK_BRIDGE_OBJECT : 39|1@0+ (1,0) [0|1] "" Vector__XXX
 SG_ CAN_TX_TRACK_ANGLE : 12|10@0- (0.1,0) [-51.2|51.1] "" Vector__XXX

BO_ 1288 Target9: 8 Vector__XXX
 SG_ CAN_TX_TRACK_WIDTH : 37|4@0+ (0.5,0) [0|7.5] "" Vector__XXX
 SG_ CAN_TX_TRACK_STATUS : 15|3@0+ (1,0) [0|7] "" Vector__XXX
 SG_ CAN_TX_TRACK_ROLLING_COUNT : 38|1@0+ (1,0) [0|1] "" Vector__XXX
 SG_ CAN_TX_TRACK_RANGE_RATE : 53|14@0- (0.01,0) [-81.92|81.91] "m/s" Vector__XXX
 SG_ CAN_TX_TRACK_RANGE_ACCEL : 33|10@0- (0.05,0) [-25.6|25.55] "m/s^2" Vector__XXX
 SG_ CAN_TX_TRACK_RANGE : 18|11@0+ (0.1,0) [0|204.7] "m" Vector__XXX
 SG_ CAN_TX_TRACK_ONCOMING : 0|1@0+ (1,0) [0|1] "" Vector__XXX
 SG_ CAN_TX_TRACK_MED_RANGE_MODE : 55|2@0+ (1,0) [0|3] "" Vector__XXX
 SG_ CAN_TX_TRACK_LAT_RATE : 7|6@0- (0.25,0) [-8|7.75] "" Vector__XXX
 SG_ CAN_TX_TRACK_GROUPING_CHANGED : 1|1@0+ (1,0) [0|1] "" Vector__XXX
 SG_ CAN_TX_TRACK_BRIDGE_OBJECT : 39|1@0+ (1,0) [0|1] "" Vector__XXX
 SG_ CAN_TX_TRACK_ANGLE : 12|10@0- (0.1,0) [-51.2|51.1] "" Vector__XXX

BO_ 1287 Target8: 8 Vector__XXX
 SG_ CAN_TX_TRACK_WIDTH : 37|4@0+ (0.5,0) [0|7.5] "" Vector__XXX
 SG_ CAN_TX_TRACK_STATUS : 15|3@0+ (1,0) [0|7] "" Vector__XXX
 SG_ CAN_TX_TRACK_ROLLING_COUNT : 38|1@0+ (1,0) [0|1] "" Vector__XXX
 SG_ CAN_TX_TRACK_RANGE_RATE : 53|14@0- (0.01,0) [-81.92|81.91] "m/s" Vector__XXX
 SG_ CAN_TX_TRACK_RANGE_ACCEL : 33|10@0- (0.05,0) [-25.6|25.55] "m/s^2" Vector__XXX
 SG_ CAN_TX_TRACK_RANGE : 18|11@0+ (0.1,0) [0|204.7] "m" Vector__XXX
 SG_ CAN_TX_TRACK_ONCOMING : 0|1@0+ (1,0) [0|1] "" Vector__XXX
 SG_ CAN_TX_TRACK_MED_RANGE_MODE : 55|2@0+ (1,0) [0|3] "" Vector__XXX
 SG_ CAN_TX_TRACK_LAT_RATE : 7|6@0- (0.25,0) [-8|7.75] "" Vector__XXX
 SG_ CAN_TX_TRACK_GROUPING_CHANGED : 1|1@0+ (1,0) [0|1] "" Vector__XXX
 SG_ CAN_TX_TRACK_BRIDGE_OBJECT : 39|1@0+ (1,0) [0|1] "" Vector__XXX
 SG_ CAN_TX_TRACK_ANGLE : 12|10@0- (0.1,0) [-51.2|51.1] "" Vector__XXX

BO_ 1285 Target6: 8 Vector__XXX
 SG_ CAN_TX_TRACK_WIDTH : 37|4@0+ (0.5,0) [0|7.5] "" Vector__XXX
 SG_ CAN_TX_TRACK_STATUS : 15|3@0+ (1,0) [0|7] "" Vector__XXX
 SG_ CAN_TX_TRACK_ROLLING_COUNT : 38|1@0+ (1,0) [0|1] "" Vector__XXX
 SG_ CAN_TX_TRACK_RANGE_RATE : 53|14@0- (0.01,0) [-81.92|81.91] "m/s" Vector__XXX
 SG_ CAN_TX_TRACK_RANGE_ACCEL : 33|10@0- (0.05,0) [-25.6|25.55] "m/s^2" Vector__XXX
 SG_ CAN_TX_TRACK_RANGE : 18|11@0+ (0.1,0) [0|204.7] "m" Vector__XXX
 SG_ CAN_TX_TRACK_ONCOMING : 0|1@0+ (1,0) [0|1] "" Vector__XXX
 SG_ CAN_TX_TRACK_MED_RANGE_MODE : 55|2@0+ (1,0) [0|3] "" Vector__XXX
 SG_ CAN_TX_TRACK_LAT_RATE : 7|6@0- (0.25,0) [-8|7.75] "" Vector__XXX
 SG_ CAN_TX_TRACK_GROUPING_CHANGED : 1|1@0+ (1,0) [0|1] "" Vector__XXX
 SG_ CAN_TX_TRACK_BRIDGE_OBJECT : 39|1@0+ (1,0) [0|1] "" Vector__XXX
 SG_ CAN_TX_TRACK_ANGLE : 12|10@0- (0.1,0) [-51.2|51.1] "" Vector__XXX

BO_ 1286 Target7: 8 Vector__XXX
 SG_ CAN_TX_TRACK_WIDTH : 37|4@0+ (0.5,0) [0|7.5] "" Vector__XXX
 SG_ CAN_TX_TRACK_STATUS : 15|3@0+ (1,0) [0|7] "" Vector__XXX
 SG_ CAN_TX_TRACK_ROLLING_COUNT : 38|1@0+ (1,0) [0|1] "" Vector__XXX
 SG_ CAN_TX_TRACK_RANGE_RATE : 53|14@0- (0.01,0) [-81.92|81.91] "m/s" Vector__XXX
 SG_ CAN_TX_TRACK_RANGE_ACCEL : 33|10@0- (0.05,0) [-25.6|25.55] "m/s^2" Vector__XXX
 SG_ CAN_TX_TRACK_RANGE : 18|11@0+ (0.1,0) [0|204.7] "m" Vector__XXX
 SG_ CAN_TX_TRACK_ONCOMING : 0|1@0+ (1,0) [0|1] "" Vector__XXX
 SG_ CAN_TX_TRACK_MED_RANGE_MODE : 55|2@0+ (1,0) [0|3] "" Vector__XXX
 SG_ CAN_TX_TRACK_LAT_RATE : 7|6@0- (0.25,0) [-8|7.75] "" Vector__XXX
 SG_ CAN_TX_TRACK_GROUPING_CHANGED : 1|1@0+ (1,0) [0|1] "" Vector__XXX
 SG_ CAN_TX_TRACK_BRIDGE_OBJECT : 39|1@0+ (1,0) [0|1] "" Vector__XXX
 SG_ CAN_TX_TRACK_ANGLE : 12|10@0- (0.1,0) [-51.2|51.1] "" Vector__XXX

BO_ 1284 Target5: 8 Vector__XXX
 SG_ CAN_TX_TRACK_WIDTH : 37|4@0+ (0.5,0) [0|7.5] "" Vector__XXX
 SG_ CAN_TX_TRACK_STATUS : 15|3@0+ (1,0) [0|7] "" Vector__XXX
 SG_ CAN_TX_TRACK_ROLLING_COUNT : 38|1@0+ (1,0) [0|1] "" Vector__XXX
 SG_ CAN_TX_TRACK_RANGE_RATE : 53|14@0- (0.01,0) [-81.92|81.91] "m/s" Vector__XXX
 SG_ CAN_TX_TRACK_RANGE_ACCEL : 33|10@0- (0.05,0) [-25.6|25.55] "m/s^2" Vector__XXX
 SG_ CAN_TX_TRACK_RANGE : 18|11@0+ (0.1,0) [0|204.7] "m" Vector__XXX
 SG_ CAN_TX_TRACK_ONCOMING : 0|1@0+ (1,0) [0|1] "" Vector__XXX
 SG_ CAN_TX_TRACK_MED_RANGE_MODE : 55|2@0+ (1,0) [0|3] "" Vector__XXX
 SG_ CAN_TX_TRACK_LAT_RATE : 7|6@0- (0.25,0) [-8|7.75] "" Vector__XXX
 SG_ CAN_TX_TRACK_GROUPING_CHANGED : 1|1@0+ (1,0) [0|1] "" Vector__XXX
 SG_ CAN_TX_TRACK_BRIDGE_OBJECT : 39|1@0+ (1,0) [0|1] "" Vector__XXX
 SG_ CAN_TX_TRACK_ANGLE : 12|10@0- (0.1,0) [-51.2|51.1] "" Vector__XXX

BO_ 1283 Target4: 8 Vector__XXX
 SG_ CAN_TX_TRACK_WIDTH : 37|4@0+ (0.5,0) [0|7.5] "" Vector__XXX
 SG_ CAN_TX_TRACK_STATUS : 15|3@0+ (1,0) [0|7] "" Vector__XXX
 SG_ CAN_TX_TRACK_ROLLING_COUNT : 38|1@0+ (1,0) [0|1] "" Vector__XXX
 SG_ CAN_TX_TRACK_RANGE_RATE : 53|14@0- (0.01,0) [-81.92|81.91] "m/s" Vector__XXX
 SG_ CAN_TX_TRACK_RANGE_ACCEL : 33|10@0- (0.05,0) [-25.6|25.55] "m/s^2" Vector__XXX
 SG_ CAN_TX_TRACK_RANGE : 18|11@0+ (0.1,0) [0|204.7] "m" Vector__XXX
 SG_ CAN_TX_TRACK_ONCOMING : 0|1@0+ (1,0) [0|1] "" Vector__XXX
 SG_ CAN_TX_TRACK_MED_RANGE_MODE : 55|2@0+ (1,0) [0|3] "" Vector__XXX
 SG_ CAN_TX_TRACK_LAT_RATE : 7|6@0- (0.25,0) [-8|7.75] "" Vector__XXX
 SG_ CAN_TX_TRACK_GROUPING_CHANGED : 1|1@0+ (1,0) [0|1] "" Vector__XXX
 SG_ CAN_TX_TRACK_BRIDGE_OBJECT : 39|1@0+ (1,0) [0|1] "" Vector__XXX
 SG_ CAN_TX_TRACK_ANGLE : 12|10@0- (0.1,0) [-51.2|51.1] "" Vector__XXX

BO_ 1282 Target3: 8 Vector__XXX
 SG_ CAN_TX_TRACK_WIDTH : 37|4@0+ (0.5,0) [0|7.5] "" Vector__XXX
 SG_ CAN_TX_TRACK_STATUS : 15|3@0+ (1,0) [0|7] "" Vector__XXX
 SG_ CAN_TX_TRACK_ROLLING_COUNT : 38|1@0+ (1,0) [0|1] "" Vector__XXX
 SG_ CAN_TX_TRACK_RANGE_RATE : 53|14@0- (0.01,0) [-81.92|81.91] "m/s" Vector__XXX
 SG_ CAN_TX_TRACK_RANGE_ACCEL : 33|10@0- (0.05,0) [-25.6|25.55] "m/s^2" Vector__XXX
 SG_ CAN_TX_TRACK_RANGE : 18|11@0+ (0.1,0) [0|204.7] "m" Vector__XXX
 SG_ CAN_TX_TRACK_ONCOMING : 0|1@0+ (1,0) [0|1] "" Vector__XXX
 SG_ CAN_TX_TRACK_MED_RANGE_MODE : 55|2@0+ (1,0) [0|3] "" Vector__XXX
 SG_ CAN_TX_TRACK_LAT_RATE : 7|6@0- (0.25,0) [-8|7.75] "" Vector__XXX
 SG_ CAN_TX_TRACK_GROUPING_CHANGED : 1|1@0+ (1,0) [0|1] "" Vector__XXX
 SG_ CAN_TX_TRACK_BRIDGE_OBJECT : 39|1@0+ (1,0) [0|1] "" Vector__XXX
 SG_ CAN_TX_TRACK_ANGLE : 12|10@0- (0.1,0) [-51.2|51.1] "" Vector__XXX

BO_ 1281 Target2: 8 Vector__XXX
 SG_ CAN_TX_TRACK_WIDTH : 37|4@0+ (0.5,0) [0|7.5] "" Vector__XXX
 SG_ CAN_TX_TRACK_STATUS : 15|3@0+ (1,0) [0|7] "" Vector__XXX
 SG_ CAN_TX_TRACK_ROLLING_COUNT : 38|1@0+ (1,0) [0|1] "" Vector__XXX
 SG_ CAN_TX_TRACK_RANGE_RATE : 53|14@0- (0.01,0) [-81.92|81.91] "m/s" Vector__XXX
 SG_ CAN_TX_TRACK_RANGE_ACCEL : 33|10@0- (0.05,0) [-25.6|25.55] "m/s^2" Vector__XXX
 SG_ CAN_TX_TRACK_RANGE : 18|11@0+ (0.1,0) [0|204.7] "m" Vector__XXX
 SG_ CAN_TX_TRACK_ONCOMING : 0|1@0+ (1,0) [0|1] "" Vector__XXX
 SG_ CAN_TX_TRACK_MED_RANGE_MODE : 55|2@0+ (1,0) [0|3] "" Vector__XXX
 SG_ CAN_TX_TRACK_LAT_RATE : 7|6@0- (0.25,0) [-8|7.75] "" Vector__XXX
 SG_ CAN_TX_TRACK_GROUPING_CHANGED : 1|1@0+ (1,0) [0|1] "" Vector__XXX
 SG_ CAN_TX_TRACK_BRIDGE_OBJECT : 39|1@0+ (1,0) [0|1] "" Vector__XXX
 SG_ CAN_TX_TRACK_ANGLE : 12|10@0- (0.1,0) [-51.2|51.1] "" Vector__XXX

BO_ 1524 VehicleData3: 8 Gateway
 SG_ CAN_RX_YAW_RATE_BIAS_SHIFT : 15|1@0+ (1,0) [0|1] "" Vector__XXX
 SG_ CAN_RX_WHEELBASE : 55|8@0+ (2,200) [200|710] "cm" Vector__XXX
 SG_ CAN_RX_STEERING_GEAR_RATIO : 63|8@0+ (0.125,0) [0|31.875] "" Vector__XXX
 SG_ CAN_RX_OVERSTEER_UNDERSTEER : 7|8@0- (1,0) [-128|127] "%" Vector__XXX
 SG_ CAN_RX_FUNNEL_OFFSET_RIGHT : 31|8@0- (0.1,0) [-12.8|12.7] "m" Vector__XXX
 SG_ CAN_RX_FUNNEL_OFFSET_LEFT : 23|8@0- (0.1,0) [-12.8|12.7] "m" Vector__XXX
 SG_ CAN_RX_DISTANCE_REAR_AXLE : 47|8@0+ (2,200) [200|710] "cm" Vector__XXX
 SG_ CAN_RX_CW_BLOCKAGE_TRESHOLD : 39|8@0+ (0.0078125,0) [0|1.9921875] "" Vector__XXX
 SG_ CAN_RX_BEAMWIDTH_VERT : 14|7@0+ (0.0625,0) [0|7.9375] "deg" Vector__XXX

BO_ 1523 FactoryAlignment: 8 Gateway

BO_ 1522 Vehicle_Data2: 8 Gateway
 SG_ CAN_RX_WHEEL_SLIP : 41|2@0+ (1,0) [0|3] "" Vector__XXX
 SG_ CAN_RX_SERV_ALIGN_UPDATES_NEED : 55|8@0+ (1,0) [0|255] "" Vector__XXX
 SG_ CAN_RX_SERV_ALIGN_TYPE : 47|1@0+ (1,0) [0|1] "" Vector__XXX
 SG_ CAN_RX_RADAR_HEIGHT : 38|7@0+ (1,0) [0|127] "cm" Vector__XXX
 SG_ CAN_RX_RADAR_FOV_MR : 30|7@0+ (1,0) [0|127] "deg" Vector__XXX
 SG_ CAN_RX_RADAR_FOV_LR : 19|5@0+ (1,0) [0|31] "deg" Vector__XXX
 SG_ CAN_RX_LONG_ACCEL_VALIDITY : 7|1@0+ (1,0) [0|1] "" Vector__XXX
 SG_ CAN_RX_LONG_ACCEL : 12|9@0- (0.03125,0) [-8|7.96875] "m/s^2" Vector__XXX
 SG_ CAN_RX_LAT_ACCEL_VALIDITY : 6|1@0+ (1,0) [0|1] "" Vector__XXX
 SG_ CAN_RX_LAT_ACCEL : 5|9@0- (0.03125,0) [-8|7.96875] "m/s^2" Vector__XXX
 SG_ CAN_RX_AUTO_ALIGN_DISABLE : 39|1@0+ (1,0) [0|1] "" Vector__XXX
 SG_ CAN_RX_AUTO_ALIGN_CONVERGED : 42|1@0+ (1,0) [0|1] "" Vector__XXX
 SG_ CAN_RX_ANGLE_MOUNTING_OFFSET : 63|8@0- (0.0625,0) [-8|7.9375] "deg" Vector__XXX
 SG_ CAN_RX_AALIGN_AVG_CTR_TOTAL : 45|3@0+ (250,250) [250|2000] "" Vector__XXX

BO_ 1512 CIPV_Targets_Etc: 8 ESR

BO_ 1511 ESR_History_Fault: 8 ESR

BO_ 1510 ESR_Active_Fault: 8 ESR

BO_ 1508 AD_Data: 8 ESR

BO_ 1489 SensorValidation2: 8 ESR
 SG_ CAN_TX_VALID_MR_SN : 7|8@0+ (1,0) [0|255] "" Vector__XXX
 SG_ CAN_TX_VALID_MR_RANGE_RATE : 31|16@0- (0.0078125,0) [-256|255.9921875] "m/s" Vector__XXX
 SG_ CAN_TX_VALID_MR_RANGE : 15|16@0+ (0.0078125,0) [0|511.9921875] "m" Vector__XXX
 SG_ CAN_TX_VALID_MR_POWER : 63|8@0- (1,0) [-128|127] "db" Vector__XXX
 SG_ CAN_TX_VALID_MR_ANGLE : 40|16@1- (0.0625,0) [-2048|2047.9375] "deg" Vector__XXX

BO_ 1488 SensorValidation: 8 ESR
 SG_ CAN_TX_VALID_LR_SN : 7|8@0+ (1,0) [0|255] "" Vector__XXX
 SG_ CAN_TX_VALID_LR_RANGE_RATE : 31|16@0- (0.0078125,0) [-256|255.9921875] "m/s" Vector__XXX
 SG_ CAN_TX_VALID_LR_RANGE : 15|16@0+ (0.0078125,0) [0|511.9921875] "m" Vector__XXX
 SG_ CAN_TX_VALID_LR_POWER : 63|8@0- (1,0) [-128|127] "db" Vector__XXX
 SG_ CAN_TX_VALID_LR_ANGLE : 47|16@0- (0.0625,0) [-2048|2047.9375] "deg" Vector__XXX

BO_ 1280 Target1: 8 ESR
 SG_ CAN_TX_TRACK_WIDTH : 37|4@0+ (0.5,0) [0|7.5] "" Vector__XXX
 SG_ CAN_TX_TRACK_STATUS : 15|3@0+ (1,0) [0|7] "" Vector__XXX
 SG_ CAN_TX_TRACK_ROLLING_COUNT : 38|1@0+ (1,0) [0|1] "" Vector__XXX
 SG_ CAN_TX_TRACK_RANGE_RATE : 53|14@0- (0.01,0) [-81.92|81.91] "m/s" Vector__XXX
 SG_ CAN_TX_TRACK_RANGE_ACCEL : 33|10@0- (0.05,0) [-25.6|25.55] "m/s^2" Vector__XXX
 SG_ CAN_TX_TRACK_RANGE : 18|11@0+ (0.1,0) [0|204.7] "m" Vector__XXX
 SG_ CAN_TX_TRACK_ONCOMING : 0|1@0+ (1,0) [0|1] "" Vector__XXX
 SG_ CAN_TX_TRACK_MED_RANGE_MODE : 55|2@0+ (1,0) [0|3] "" Vector__XXX
 SG_ CAN_TX_TRACK_LAT_RATE : 7|6@0- (0.25,0) [-8|7.75] "" Vector__XXX
 SG_ CAN_TX_TRACK_GROUPING_CHANGED : 1|1@0+ (1,0) [0|1] "" Vector__XXX
 SG_ CAN_TX_TRACK_BRIDGE_OBJECT : 39|1@0+ (1,0) [0|1] "" Vector__XXX
 SG_ CAN_TX_TRACK_ANGLE : 12|10@0- (0.1,0) [-51.2|51.1] "" Vector__XXX

BO_ 1265 SensorInput: 8 Gateway
 SG_ CAN_RX_USE_ANGLE_MISALIGNMENT : 23|1@0+ (1,0) [0|0] "" Vector__XXX
 SG_ CAN_RX_SCAN_INDEX_ACK : 7|16@0+ (1,0) [0|65535] "" Vector__XXX
 SG_ CAN_RX_LATERAL_MOUNTING_OFFSET : 47|8@0- (0.01563,0) [-2.00064|1.98501] "m" Vector__XXX
 SG_ CAN_RX_WIPER_STATUS : 57|1@0+ (1,0) [0|1] "" Vector__XXX
 SG_ CAN_RX_VOLVO_SHORT_TRACK_ROC : 31|4@0- (500,0) [-4000|3500] "m" Vector__XXX
 SG_ CAN_RX_VEHICLE_SPEED_VALIDITY : 61|1@0+ (1,0) [0|1] "" Vector__XXX
 SG_ CAN_RX_TURN_SIGNAL_STATUS : 63|2@0+ (1,0) [0|3] "" Vector__XXX
 SG_ CAN_RX_RAW_DATA_ENABLE : 56|1@0+ (1,0) [0|1] "" Vector__XXX
 SG_ CAN_RX_RADAR_CMD_RADIATE : 55|1@0+ (1,0) [0|1] "" Vector__XXX
 SG_ CAN_RX_MR_ONLY_TRANSMIT : 25|1@0+ (1,0) [0|0] "" Vector__XXX
 SG_ CAN_RX_MMR_UPSIDE_DOWN : 60|1@0+ (1,0) [0|1] "" Vector__XXX
 SG_ CAN_RX_MAXIMUM_TRACKS : 53|6@0+ (1,0) [0|63] "" Vector__XXX
 SG_ CAN_RX_LR_ONLY_TRANSMIT : 24|1@0+ (1,0) [0|0] "" Vector__XXX
 SG_ CAN_RX_HIGH_YAW_ANGLE : 21|6@0- (1,0) [-32|31] "deg" Vector__XXX
 SG_ CAN_RX_GROUPING_MODE : 59|2@0+ (1,0) [0|3] "" Vector__XXX
 SG_ CAN_RX_CLEAR_FAULTS : 22|1@0- (1,0) [0|0] "" Vector__XXX
 SG_ CAN_RX_BLOCKAGE_DISABLE : 54|1@0+ (1,0) [0|1] "" Vector__XXX
 SG_ CAN_RX_ANGLE_MISALIGNMENT : 39|8@0- (0.0625,0) [-8|7.9375] "deg" Vector__XXX

BO_ 1264 Vehicle_Data: 8 Gateway
 SG_ CAN_RX_YAW_RATE_VALIDITY : 31|1@0+ (1,0) [0|0] "" Vector__XXX
 SG_ CAN_RX_YAW_RATE : 11|12@0- (0.0625,0) [-128|127.9375] "deg/s" Vector__XXX
 SG_ CAN_RX_VEHICLE_SPEED_DIRECTION : 12|1@0+ (1,0) [0|1] "" Vector__XXX
 SG_ CAN_RX_VEHICLE_SPEED : 7|11@0+ (0.0625,0) [0|127.9375] "m/s" Vector__XXX
 SG_ CAN_RX_RADIUS_CURVATURE : 29|14@0- (1,0) [-8192|8191] "m" Vector__XXX
 SG_ CAN_RX_STEERING_VALIDITY : 47|1@0+ (1,0) [0|1] "" Vector__XXX
 SG_ CAN_RX_STEERING_ANGLE_SIGN : 46|1@0+ (1,0) [0|1] "" Vector__XXX
 SG_ CAN_RX_STEERING_ANGLE_RATE_SIGN : 30|1@0+ (1,0) [0|1] "" Vector__XXX
 SG_ CAN_RX_STEERING_ANGLE_RATE : 50|11@0+ (1,0) [0|2047] "deg/s" Vector__XXX
 SG_ CAN_RX_STEERING_ANGLE : 45|11@0+ (1,0) [0|2047] "deg" Vector__XXX

BO_ 1251 ESR_Output_InPath: 8 ESR
 SG_ CAN_TX_PATH_ID_ACC_MOVE : 15|8@0+ (1,0) [0|255] "" Vector__XXX
 SG_ CAN_TX_TRUCK_TARGET_DET : 7|1@0+ (1,0) [0|1] "" Vector__XXX
 SG_ CAN_TX_SIDELOBE_BLOCKATE : 5|1@0+ (1,0) [0|1] "" Vector__XXX
 SG_ CAN_TX_ROLLING_COUNT_3 : 1|2@0+ (1,0) [0|3] "" Vector__XXX
 SG_ CAN_TX_PATH_ID_FCW_STAT : 47|8@0+ (1,0) [0|255] "" Vector__XXX
 SG_ CAN_TX_PATH_ID_FCW_MOVE : 39|8@0+ (1,0) [0|255] "" Vector__XXX
 SG_ CAN_TX_PATH_ID_CMBB_STAT : 31|8@0+ (1,0) [0|255] "" Vector__XXX
 SG_ CAN_TX_PATH_ID_CMBB_MOVE : 23|8@0+ (1,0) [0|255] "" Vector__XXX
 SG_ CAN_TX_PATH_ID_ACC_STAT : 63|8@0+ (1,0) [0|255] "" Vector__XXX
 SG_ CAN_TX_PARTIAL_BLOCKAGE : 4|1@0+ (1,0) [0|1] "" Vector__XXX
 SG_ CAN_TX_LR_ONLY_GRATING_LOBE_DET : 6|1@0+ (1,0) [0|1] "" Vector__XXX
 SG_ CAN_TX_LMR_LR_MODE : 3|2@0+ (1,0) [0|3] "" Vector__XXX
 SG_ CAN_TX_AUTO_ALIGN_ANGLE : 55|8@0- (0.0625,0) [-8|7.9375] "" Vector__XXX

BO_ 1250 ESR_SW: 8 ESR
 SG_ CAN_TX_SW_VERSION_PLD : 63|8@0+ (1,0) [0|255] "" Vector__XXX
 SG_ CAN_TX_SW_VERSION_HOST : 15|24@0+ (1,0) [0|16777215] "" Vector__XXX
 SG_ CAN_TX_SERIAL_NUM : 39|24@0+ (1,0) [0|16777215] "" Vector__XXX
 SG_ CAN_TX_INTERFACE_VERSION : 7|4@0+ (1,0) [0|15] "" Vector__XXX
 SG_ CAN_TX_HW_VERSION : 3|4@0+ (1,0) [0|15] "" Vector__XXX

BO_ 1249 ESR_Status2: 8 ESR
 SG_ CAN_TX_YAW_RATE_BIAS : 47|8@0- (0.125,0) [-16|15.875] "" Vector__XXX
 SG_ CAN_TX_XCVR_OPERATIONAL : 12|1@0+ (1,0) [0|1] "" Vector__XXX
 SG_ CAN_TX_VEH_SPD_COMP_FACTOR : 39|6@0- (0.00195,1) [0.9376|1.06045] "" Vector__XXX
 SG_ CAN_TX_TEMPERATURE : 31|8@0- (1,0) [-128|127] "degC" Vector__XXX
 SG_ CAN_TX_SW_VERSION_DSP : 55|16@0+ (1,0) [0|65535] "" Vector__XXX
 SG_ CAN_TX_STEERING_ANGLE_ACK : 10|11@0+ (1,0) [0|2047] "deg" Vector__XXX
 SG_ CAN_TX_ROLLING_COUNT_2 : 1|2@0+ (1,0) [0|3] "" Vector__XXX
 SG_ CAN_TX_RAW_DATA_MODE : 11|1@0+ (1,0) [0|1] "" Vector__XXX
 SG_ CAN_TX_RANGE_PERF_ERROR : 14|1@0+ (1,0) [0|1] "" Vector__XXX
 SG_ CAN_TX_OVERHEAT_ERROR : 15|1@0+ (1,0) [0|1] "" Vector__XXX
 SG_ CAN_TX_MAXIMUM_TRACKS_ACK : 7|6@0+ (1,1) [1|64] "" Vector__XXX
 SG_ CAN_TX_INTERNAL_ERROR : 13|1@0+ (1,0) [0|1] "" Vector__XXX
 SG_ CAN_TX_GROUPING_MODE : 33|2@0+ (1,0) [0|3] "" Vector__XXX

BO_ 1248 ESR_Status: 8 ESR
 SG_ CAN_TX_COMM_ERROR : 14|1@0+ (1,0) [0|0] "" Vector__XXX
 SG_ CAN_TX_RADIUS_CURVATURE_CALC : 13|14@0- (1,0) [-8192|8191] "" Vector__XXX
 SG_ CAN_TX_YAW_RATE_CALC : 47|12@0- (0.0625,0) [-128|127.9375] "deg/s" Vector__XXX
 SG_ CAN_TX_VEHICLE_SPEED_CALC : 50|11@0+ (0.0625,0) [0|127.9375] "m/s" Vector__XXX
 SG_ CAN_TX_DSP_TIMESTAMP : 5|7@0+ (2,0) [0|254] "ms" Vector__XXX
 SG_ CAN_TX_SCAN_INDEX : 31|16@0+ (1,0) [0|65535] "" Vector__XXX
 SG_ CAN_TX_ROLLING_COUNT_1 : 6|2@1+ (1,0) [0|3] "" Vector__XXX

BO_ 1344 Track_Sensor: 8 ESR
 SG_ Track_Counter : 7|8@0+ (1,0) [0|9] "" Vector__XXX

CM_ SG_ 85 BrakePedalActive2 "Active during braking";
CM_ SG_ 85 NEW_SIGNAL_1 "Not yet figured out.";
CM_ SG_ 85 BrakePedalActive "Brake pedal pushed. Behaves like a pressure threshold (~75-100 on 0x1B0 BrakePress0), not a switch.";
CM_ SG_ 8 SteeringDirection "1=Right turn, 0=Left turn. Steering wheel pointing left or right from center (0 deg).";
CM_ SG_ 8 RelativeTurnDirection "1=Right turn, 0=Left turn. Steering wheel currently turning the way.";
CM_ SG_ 101 NEW_SIGNAL_1 "Rate of something?";
CM_ SG_ 192 TransmissionGear "0 = 1st gear, 1= 2nd gear...";
CM_ SG_ 681 TurnSignal "0 = Nothing, 1= Left, 3=Right";
CM_ SG_ 681 HighBeamOn "1=HighBeam On, 0=HighBeam Off";
CM_ SG_ 48 ACCStatusTracking "ACC Tracking vehicle, distance control.";
CM_ SG_ 48 ACCStatusOnOff "Turns one after pressing on/off button on steering wheel";
CM_ SG_ 48 FCWSomething "All bit set during fcw";
CM_ SG_ 48 StatusSomething "Some status changes when zeroing DTCs";
CM_ SG_ 208 TrqLim "Used in checksum calculation, Limit directional torque based on the number.";
CM_ SG_ 208 Checksum "Checksum calculated as a one-complement addition of LKAAngleRequest+LKADirection+Unkown, Zeros used to pad missing bits.";
CM_ SG_ 208 SET_X_02 "Bit 0 = Vibrate steering wheel., Bit 1 = Heartbeat";
CM_ SG_ 352 LkaDimLine "Not true, but follows lka steer direction.";
CM_ SG_ 352 NEW_SIGNAL_1 "Turned one. Got LKA service needed can this be the one?";
CM_ SG_ 640 ACC_TractionRequest "Low 10 bits of the bytes 6-7 word (the original NEW_SIGNAL_1 49|10 restored). ACC drive/coast demand, medium-low confidence. ~490-600 at cruise, ~610-650 when accelerating (+0.8 to +1.5 m/s2), 0 in braking/decel (brake mode, incl. coasting down). Fit ~83-84 counts per m/s2 (accel 0.5 s ahead) in two routes (15 km/h route R2 0.80; highway route R2 0.30, speed term unstable). Resembles V60 traction request (97*a - 6, 0 in brake mode). Saturates near ~630. Hydraulic brake target not yet identified; brake request flag is in 0x160.";
CM_ SG_ 640 Byte_6_b7_6 "Always 3 (bits 15-14 of the word = 11), matching the V60 FSM4 brake word flags (0x8000 and 0x4000).";
CM_ SG_ 640 Byte_6_b5_3 "Bits 13-11 of the word, observed constant at 3 (011). Meaning unknown.";
CM_ SG_ 640 Byte_6_b2 "Bit 10 of the word. Clear whenever 0x270 byte 4 = 175 (11,700 of 11,708 frames in a manual drive; 10,540 of 10,544 in a highway ACC route), set otherwise. 175 is NOT ACC (seen with no ACC at all); most likely tied to openpilot being engaged, unproven. Explains the 0xD800 vs 0xDC00 floors seen in different routes.";
CM_ SG_ 640 SpeedTarget "SpeedTarget ACC (noisy bf starting acc Jumps from 0->252->0)";
CM_ BO_ 352 "0x160, camera to car (bus 2 -> relayed to bus 0), 50 Hz. Every ~4th-5th frame is a masked variant (Byte_0=0, Byte_2=0/32, Byte_3~20, Byte_5=0/33). No simple counter/checksum found (byte 7/4 are not XOR or sum of the others).";
CM_ SG_ 352 ACC_BrakeRequest "UNCONFIRMED (medium-low). Set ~0.44 s before hydraulic pressure rises at both ACC braking events (586.3 s, 873.2 s). Not set on driver braking while moving. Also stays set at standstill with brake held. One 0.5 s false blip seen at 751 s with no braking. Also set in masked frames. Confirmed again in dashcam route (stock ACC stop 34-51 s) and 15 km/h route (decels at 110 s and 126 s): flag precedes hydraulic pressure and appears on ACC decel even without hydraulic braking.";
CM_ SG_ 352 ACC_BrakeRequest_B "UNCONFIRMED. Same behaviour as ACC_BrakeRequest. Always set when ACC_BrakeRequest is set, and also sometimes alone (2270 frames).";
CM_ SG_ 352 Byte_4 "Sawtooth sweep (~-40 per 100 ms, wrapping 255 to 0) while ACC brakes. Otherwise mostly holds steady (idle values 3-7). Ramp, not a plain target or counter. Replaces old NEW_SIGNAL_4 (36|5).";
CM_ SG_ 352 Byte_3 "84 -> 83 -> 82 drifts down during ACC braking. Masked frames ~20/19/18.";
CM_ SG_ 352 Byte_2_b4_0 "Byte 2 is 213 idle, 245 once ACC braking starts (only bit 5 differs). Replaces old NEW_SIGNAL_3 (7|24).";
CM_ SG_ 624 Byte_4 "Reads 0x87 or 0x00 with stock ACC engaged, so it is NOT the ACC engaged state. 0xAF (175) appears with no ACC at all (e.g. 4 stretches in a 2238 s manual drive) and begins before ACC is switched on, then continues after it ends; most likely tied to openpilot being engaged, unproven. Other values seen: 0x28 (40), 0x9F, 0xA7. Bit 10 of the 0x280 word (Byte_6_b2) is clear exactly when this reads 175.";
CM_ SG_ 528 LKA_State "0x210 byte 0 bit 2, 40 Hz, bus 0. Confirmed working as intended on the volvo_redlight branch. Seen in logs: on for the whole of a 1335 s manual drive and a highway route, never on in the 15 km/h set-speed route (likely LKA switched off for that drive). Follows the LKA enabled setting, not activity.";
CM_ SG_ 624 ACC_LeadDecelRaw "Signed 16-bit, -1 idle (about -230 steady with a lead in some logs). Goes strongly negative (to -3300 and lower) when a lead car ahead is braking, and stayed -1 during ACC own set-speed decels (-1.8 m/s2), so it is a lead-related decel demand, NOT the ACC decel request. Never positive. Low confidence.";
CM_ SG_ 624 Byte_0 "Always 0";
CM_ SG_ 624 Byte_1 "Always 0";
CM_ SG_ 624 Byte_5 "0 or 2; 2 seen when throttle is on";
CM_ SG_ 624 Byte_6 "Always 0";
CM_ SG_ 624 Byte_7 "Always 0";
CM_ SG_ 640 Byte_0 "0x40, bit 3 sometimes set";
CM_ SG_ 864 ACC_DemandChangeFlag "10 Hz. Idle 164 (163 in manual). Under ACC it spikes high (~244-254) as ACC begins re-accelerating and low (0-21) when it begins decelerating. Event marker, not a request value. Medium confidence.";
CM_ SG_ 853 TargetSpeedOdo "Probably target speed odo";
CM_ SG_ 853 LaneMarkingsOdo "Bit 3=Left lane, Bit 2=Right lane, Bit 1=LKA on?, Bit 0=?";
CM_ SG_ 709 SpeedTargetACC "SpeedTargetACC";
CM_ SG_ 709 ACC_PropulsionFeedback "0x2C5 byte 7, ECM to camera (bus 0, echoed on bus 130), 16.7 Hz. Follows accelerator pedal (r~0.8). Pedal at zero: ~0 in manual driving, ~21 under ACC (ACC torque). Reads 0 during braking, ~25 at cruise, 160+ at +1.5 m/s2 (fit ~70*a+25). ECM output / feedback, NOT a request. Medium-low confidence.";
CM_ SG_ 224 rate_of_something "Seems to be some kind of torque rather than rate.";
CM_ SG_ 224 OneDuringDriving "Set to 1 when vehicle is rolling.";
CM_ SG_ 293 byte7 "Bit0=0 when gearshift in park, else 1";
CM_ SG_ 293 LKAActive "Bit0=0 when gear in park otherwise =1, Bit1=1 when LKA Active, 0 when not active. Bit2=? Bit3=?";
CM_ SG_ 16 ACCOnOffBtn "Cruise control on/off button pressed";
CM_ SG_ 16 ACCSetBtn "Acc Set button (+) pressed";
CM_ SG_ 16 ACCStopBtn "ACC Stop button pressed";
CM_ SG_ 16 ACCResumeBtn "ACC Resume button pressed";
CM_ SG_ 16 ACCMinusBtn "ACC Minus (-) button pressed";
CM_ SG_ 16 TimeGapIncreaseBtn "Increase the time gap on ACC";
CM_ SG_ 16 TimeGapDecreaseBtn "Decrease the time gap on ACC";
CM_ SG_ 245 counter0 "Speed based counter";
CM_ SG_ 245 WhlSpdLF "Wheel speed left front";
CM_ SG_ 245 WhlSpdRF "Wheel speed right front";
CM_ SG_ 288 WhlSpdLR "Wheel speed left rear";
CM_ SG_ 288 WhlSpdRR "Wheel speed right rear";
CM_ SG_ 64 RPMSomething "TransmissionOutput?";
CM_ SG_ 64 GearShifter "P=0, R=1, N=2, D=3";
CM_ SG_ 272 VehicleSpeedSignal "km/h";
CM_ SG_ 432 BrakePress0 "Brake pressure. (byte0&3)<<8 | byte1. Rises under ACC braking with pedal flag off (peak ~108 at red-light event). Confirmed.";
CM_ SG_ 432 BrakePress1 "Brake pressure, second copy. (byte4&3)<<8 | byte5.";
CM_ BO_ 437 "0x1B5. Brake related, 10 ms, identical on bus 0 and bus 2 (camera sees it). Idle 2F FF C0 00 00 00 00 F8. Original Counter0-3 guesses (one per wheel?) not placed: bit layout unverified.";
CM_ SG_ 114 NEW_SIGNAL_1 "Jumped from 0 -> 120 during start. Makes triangle from time to time";
CM_ SG_ 608 NEW_SIGNAL_1 "Status?";
CM_ SG_ 608 NEW_SIGNAL_2 "Classification of object?";
CM_ SG_ 608 Distance "Distance to object in front. 1908 = no lead.";
CM_ SG_ 968 PassengerSeatBelt "1 = Seatbelt latched";
CM_ SG_ 968 DriverSeatBelt "1=Seatbelt latched";
VAL_ 64 GearShifter 0 "P" 1 "R" 2 "N" 3 "D" ;
CM_ "volvo_v40_2017_ptradar.dbc - Volvo V40 (C1, 2017) test DBC. Base: volvo_v40_2017_pt.dbc + Delphi ESR radar (bus 1) + findings from the 2026-11-08 drives (r1/r2/r3). REFERENCE ONLY: the code does not load this file. Bus map in the CSV logs: 0 = car/pt, 2 = camera, 1 = radar (Delphi ESR), 128/130 = panda echoes, 192/194 = OP tx. ID CLASH: 0x540 (1344) was NEW_MSG_1 on the car side in the base DBC; on bus 1 it is the radar Track_Sensor counter. The base NEW_MSG_1 (4|13@0+) was removed here, and the radar definition kept. Load radar messages with the radar bus only.";

CM_ BO_ 1280 "Radar track 1 (0x500). 0x500-0x53F = Target1..Target64, same layout, 20 Hz each, bus 1. In route 3 only ~39% of track-slot samples held a valid target; median 27 valid tracks per 50 ms frame (max 64). Most tracks are stationary scenery (closing speed median -6.5 m/s at own speed), so they must be filtered by the in-path IDs of 0x4E3 or by range/angle/width.";
CM_ SG_ 1280 CAN_TX_TRACK_STATUS "0 no target, 1 new, 2 new updated, 3 updated, 4 coasted, 5 merged, 6 invalid coasted, 7 new coasted (per Delphi ESR ICD, not verified on this car). Route 3 counts: 0 = 571k, 3 = 180k, 4 = 104k, 1 = 42k, 2 = 28k, 7 = 9k, 5 = 2k samples.";
CM_ SG_ 1280 CAN_TX_TRACK_RANGE "Range to track, 0.1 m steps. Route 3 valid tracks: 13 m (5th pct), 54 m (median), 162 m (95th pct).";
CM_ SG_ 1280 CAN_TX_TRACK_RANGE_RATE "Closing speed, signed, 0.01 m/s. Negative = closing. Matches d(range)/dt with correlation 0.80 for the in-path lead (median error 0.7 m/s): usable but noisy.";
CM_ SG_ 1280 CAN_TX_TRACK_ANGLE "Azimuth, 0.1 deg. Valid tracks about -26 to +26 deg (5th/95th pct). Lead target median 0.1 deg.";
CM_ SG_ 1280 CAN_TX_TRACK_WIDTH "Track width, 0.5 m steps. Median 0.5 m.";
CM_ SG_ 1280 CAN_TX_TRACK_LAT_RATE "Lateral rate, 0.25 steps (unit unverified).";
CM_ SG_ 1280 CAN_TX_TRACK_RANGE_ACCEL "Range acceleration, 0.05 m/s^2. Not yet checked against the lead.";
CM_ BO_ 1344 "0x540, bus 1, ~200 Hz, 8 bytes. Byte 0 is a rolling counter 0..9, bytes 1-7 constant 0x0A in r3. The ESR DBC lists this ID as Track_Sensor with 1 byte; actual DLC here is 8. Probably a track/scan sequence counter, no sensor data.";
CM_ SG_ 1344 CAN_TX_TRACK_ROLLING_COUNT_2 "Original ESR DBC bit (4|1). In r3 the whole of byte 0 counts 0..9; see Track_Counter.";
CM_ SG_ 1344 Track_Counter "Byte 0, counts 0..9 and wraps (r3, first 12 frames: 01 02 ... 09 00 01 02). Added from the 2026-11-08 log.";
CM_ BO_ 1251 "0x4E3, bus 1, 20 Hz. The radar's own in-path target selection. Byte 1 (PATH_ID_ACC_MOVE) and byte 7 (PATH_ID_ACC_STAT) hold the track ID (1..64, 0 = none) of the moving / stationary ACC target. In r3 while stock ACC was in tracking state (0x30 byte 7 = 0x8F) the radar named an in-path moving target in 96% of frames (29% with ACC in standby). Bytes 2 and 4 (CMBB_MOVE, FCW_MOVE) carry nearly the same IDs as byte 1 in r3. Bytes 3 and 5 are mostly 0 (stationary IDs for CMBB/FCW).";
CM_ SG_ 1251 CAN_TX_PATH_ID_ACC_MOVE "Track ID of the moving in-path target used by ACC (0 = none). Most common IDs in r3: 0 (8454 frames), 61, 12, 14, 2, 8. Changes about every 8 s while tracking (20 changes in 164 s). Lead while tracking: range median 27.1 m (11 to 47 m), closing -0.7 m/s (-2.7 to +0.9), time gap 2.8 s (1.8 to 3.6 s).";
CM_ SG_ 1251 CAN_TX_PATH_ID_ACC_STAT "Track ID of the stationary in-path target for ACC (0 = none). Set only ~2% of the time while tracking in r3, so stopped-car behaviour is not covered by this log.";
CM_ SG_ 1251 CAN_TX_PARTIAL_BLOCKAGE "Stayed 0 for the whole drive: no radar blockage fault.";
CM_ SG_ 1251 CAN_TX_TRUCK_TARGET_DET "Truck target detected flag. Not examined.";
CM_ BO_ 1248 "0x4E0 ESR_Status, bus 1, 20 Hz.";
CM_ BO_ 1249 "0x4E1 ESR_Status2, bus 1, 20 Hz. Contains radar faults (internal, overheat, range-performance, comm error) and temperature. Check these first after install: none were examined in r3 beyond partial blockage.";
CM_ BO_ 1250 "0x4E2 ESR_SW, bus 1, 20 Hz. Software/hardware version and serial number: useful to identify the radar unit (Delphi ESR).";
CM_ BO_ 1264 "0x4F0 Vehicle_Data, bus 1, 50 Hz. Sent TO the radar (speed, yaw rate, steering angle, curvature). The radar needs vehicle speed and yaw to pick the in-path target. Speed unit here is m/s x 0.0625.";
CM_ BO_ 1265 "0x4F1 SensorInput, bus 1, 50 Hz. Sent TO the radar (mounting offset, misalignment, max tracks, grouping mode, wiper status, etc.).";
CM_ BO_ 1488 "0x5D0, bus 1, 20 Hz in r3. Defined in the ESR DBC (valid long-range track data). Not analysed.";
CM_ BO_ 1489 "0x5D1, bus 1, 20 Hz in r3. Defined in the ESR DBC (valid mid-range track data). Not analysed.";
CM_ BO_ 1508 "0x5E4, bus 1, 20 Hz in r3. Defined in the ESR DBC as AD_Data. Not analysed.";
CM_ "Bus 1 IDs seen in r3 that are NOT defined here or in ESR.dbc: 0x5E5-0x5E9 and 0x5F2, 0x5F4 (20 Hz each), 0x5B0-0x5B8 and 0x5BC-0x5BE (0.5 Hz each). Likely radar debug/diagnostic frames. Not analysed.";

CM_ SG_ 352 ACC_AccelRequest "NEW (replaces NEW_SIGNAL_2 56|7@1+). Byte 7 of 0x160 = stock ACC acceleration request. 192 counts is about 0 m/s^2, below = braking, above = acceleration. Fit 0.066 m/s^2 per count (raw = 192 + accel/0.066), correlation ~0.9 with measured acceleration, leads it by 0.2-0.4 s. The older WIPACCv40 estimate was 0.0556 / -10.72. Route 3 braking example: ego 49 to 5 km/h, lead 48 to 13 m, request down to about -1.4 m/s^2, then +1.1 m/s^2. Read it from bus 2 (camera original): on bus 0 with OP active it is a sparse constant 191.";
CM_ SG_ 352 Byte_2_b7_6 "Frame-type tag: 3 on the full (main) frames, 0 on the ~20% alternate (masked) frames. Main frames carry real data; alternate frames repeat the shape with Byte_3 about 18-21.";
CM_ SG_ 352 Byte_3 "Main frames (tag 3): 70-100 = measured acceleration feedback. Alternate frames about 18-21. Drifts 84 -> 83 -> 82 during ACC braking.";
CM_ SG_ 352 Byte_2_b4_0 "Route dependent (21 / 29 / 30 / 8-31 seen); not a counter. Byte 2 idle 213, 245 once ACC braking starts (only bit 5, ACC_BrakeRequest, differs).";

CM_ SG_ 48 ACCStatusActive "Old signal name. See byte 7 of 0x30 on bus 2 (camera original; bus 0 shows 0x88 while OP is active): 0x88 off, 0x8A standby, 0x8E active no lead, 0x8F active tracking a lead, 0x9x same states with the time-gap pulse bit set.";
CM_ SG_ 432 BrakeStatus "Byte 2 bits 0-2 of 0x1B0 (bus 0, ~50 Hz). Raw byte 2 seen on 2026-11-08: 0xA0 idle (also pedal presses, ACC off), 0xA5 = ACC braking (5), 0xA1 = 1 seen just before/after an ACC braking event, 0xE1 / 0xE0 = ACC holding the car at standstill (bit 6 set; value 1 or 0). The pedal never produced 0xA5. ACC braking trips the 0x55 pressure bits (24 and 38), which makes OP see brakePressed and disengage. volvo.h and carstate.py ignore the pressure bits while BrakeStatus == 5. NOTE: an earlier version of this comment used a shifted (bits 2-4) reading and called ACC braking 1; the DBC signal here (value 5) was right.";
VAL_ 432 BrakeStatus 0 "None" 1 "ACC hold or transition (0xA1 / 0xE1)" 5 "ACC braking (0xA5)" ;
CM_ BO_ 85 "0x55 PedalandBrake. Bits 24 and 38 are pressure thresholds that ACC braking also trips. OP carstate brakePressed = BrakePedalActive2 or BrakePedalActive; panda volvo.h also sets brake_pressed from bits 24/38 for C1. This is why stock ACC braking disengages OP. Do NOT use these bits to detect the driver pedal while ACC is on.";
VAL_ 1264 CAN_RX_YAW_RATE_VALIDITY 1 "Valid" 0 "Invalid" ;
VAL_ 1264 CAN_RX_VEHICLE_SPEED_DIRECTION 1 "Reverse" 0 "Forward" ;
VAL_ 1264 CAN_RX_STEERING_VALIDITY 1 "True" 0 "False" ;
VAL_ 1264 CAN_RX_STEERING_ANGLE_SIGN 1 "Right Clockwise" 0 "Left CounterClockwise" ;
VAL_ 1264 CAN_RX_STEERING_ANGLE_RATE_SIGN 1 "Right Clockwise" 0 "Left CounterClockwise" ;
VAL_ 1280 CAN_TX_TRACK_STATUS 0 "No target" 1 "New target" 2 "New updated target" 3 "Updated target" 4 "Coasted target" 5 "Merged target" 6 "Invalid coasted target" 7 "New coasted target" ;
CM_ SG_ 432 BrakeHold "Byte 2 bit 6 of 0x1B0. Set (0xE0/0xE1) while stock ACC holds the car at standstill. Only seen with ACC active. volvo.h and carstate.py treat it as ACC-owned braking while ACC is active.";
